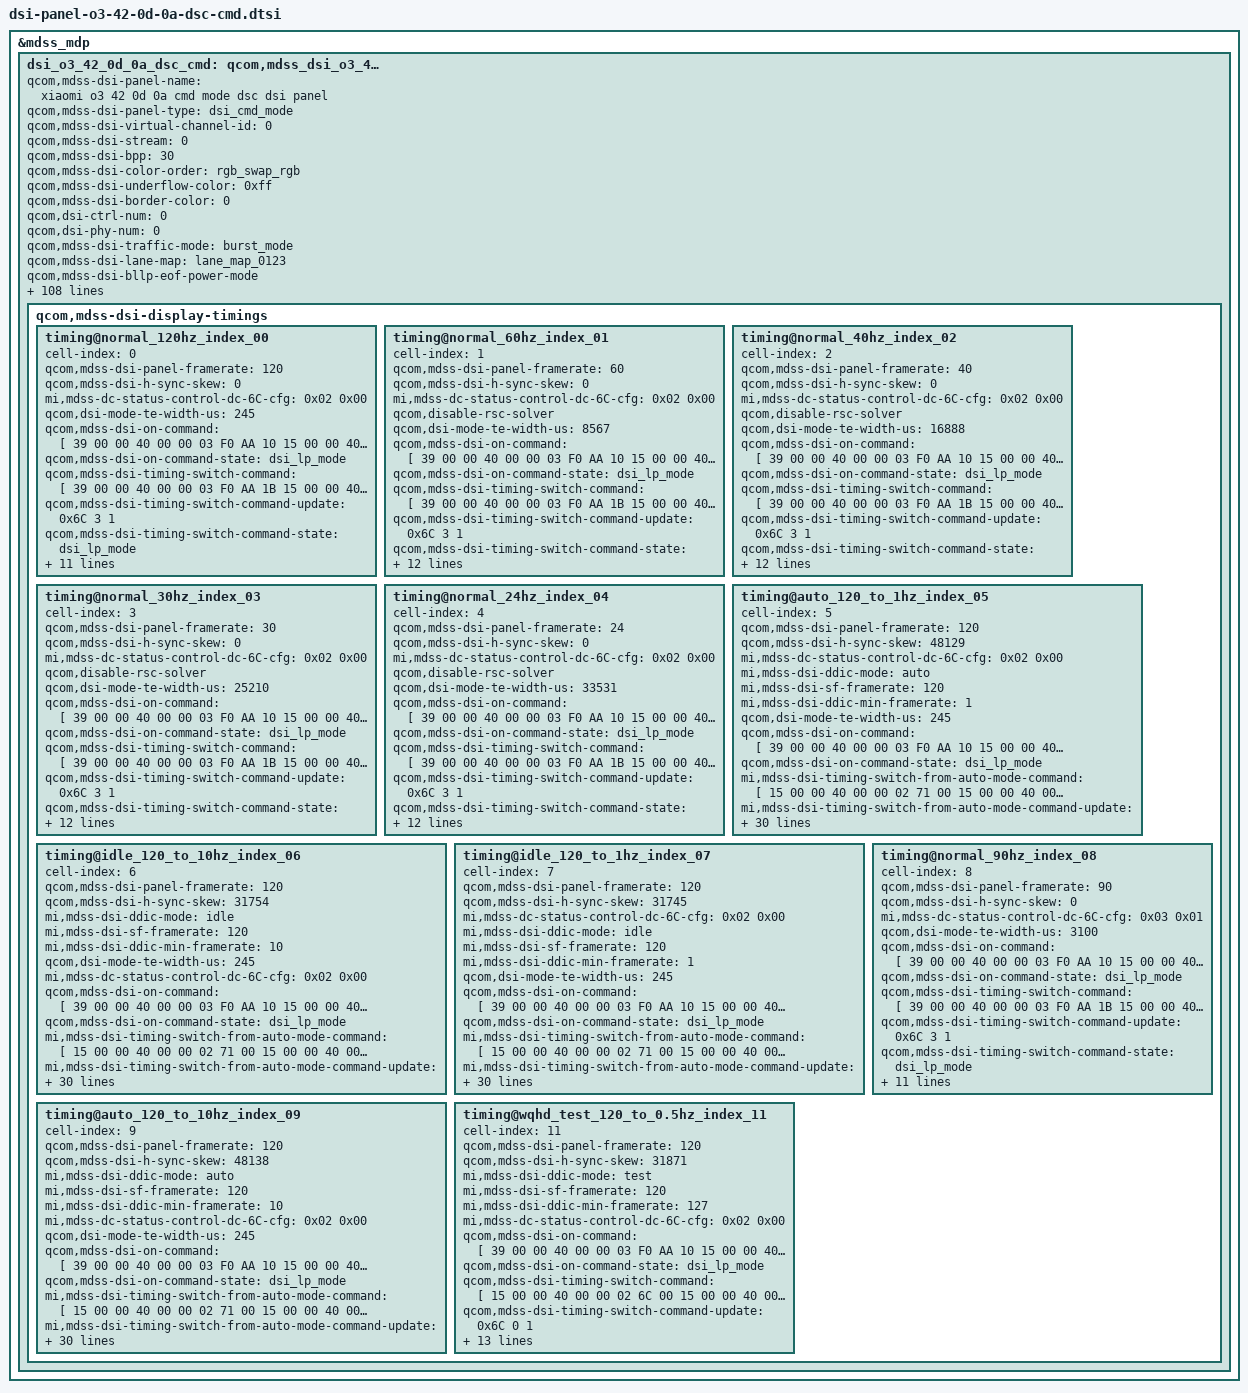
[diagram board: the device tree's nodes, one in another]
&mdss_mdp {
	dsi_o3_42_0d_0a_dsc_cmd: qcom,mdss_dsi_o3_42_0d_0a_dsc_cmd {
		qcom,mdss-dsi-panel-name = "xiaomi o3 42 0d 0a cmd mode dsc dsi panel";
		qcom,mdss-dsi-panel-type = "dsi_cmd_mode";
		qcom,mdss-dsi-virtual-channel-id = <0>;
		qcom,mdss-dsi-stream = <0>;
		qcom,mdss-dsi-bpp = <30>;
		qcom,mdss-dsi-color-order = "rgb_swap_rgb";
		qcom,mdss-dsi-underflow-color = <0xff>;
		qcom,mdss-dsi-border-color = <0>;
		qcom,dsi-ctrl-num = <0>;
		qcom,dsi-phy-num = <0>;

		qcom,mdss-dsi-traffic-mode = "burst_mode";
		qcom,mdss-dsi-lane-map = "lane_map_0123";
		qcom,mdss-dsi-bllp-eof-power-mode;
		qcom,mdss-dsi-bllp-power-mode;
		qcom,mdss-dsi-lane-0-state;
		qcom,mdss-dsi-lane-1-state;
		qcom,mdss-dsi-lane-2-state;
		qcom,mdss-dsi-lane-3-state;
		qcom,mdss-dsi-dma-trigger = "trigger_sw";
		qcom,mdss-dsi-mdp-trigger = "none";
		qcom,mdss-dsi-reset-sequence = <0 15>, <1 25>;
		qcom,mdss-pan-physical-width-dimension = <663>;
		qcom,mdss-pan-physical-height-dimension = <1473>;
		qcom,mdss-dsi-te-pin-select = <1>;
		qcom,mdss-dsi-wr-mem-start = <0x2c>;
		qcom,mdss-dsi-wr-mem-continue = <0x3c>;
		qcom,mdss-dsi-te-dcs-command = <1>;
		qcom,mdss-dsi-te-check-enable;
		qcom,mdss-dsi-te-using-te-pin;
		qcom,mdss-dsi-tx-eot-append;
		qcom,mdss-dsi-lp11-init;
		qcom,mdss-dsi-panel-hdr-enabled;
		qcom,mdss-dsi-panel-hdr-color-primaries = <14500 15500 32000 17000 15500 30000 8000 3000>;
		qcom,mdss-dsi-panel-peak-brightness = <32000000>;
		qcom,mdss-dsi-panel-blackness-level = <3230>;

		qcom,mdss-dsi-bl-inverted-dbv;
		qcom,bl-update-flag = "delay_until_first_frame";

		qcom,mdss-dsi-dma-schedule-line = <1>;
		qcom,mdss-dsi-dma-schedule-window = <50>;

		mi,panel-id = <0x00004F33 0x00420D0A>;

		mi,panel-on-dimming-delay = <120>;
		mi,max-brightness-clone = <16383>;

		mi,need-update-gamma-befor-init;

		/* IRQF_ONESHOT | IRQF_TRIGGER_HEIGH */
		mi,esd-err-irq-gpio = <&tlmm 87 0x2004>;
		mi,esd-err-irq-gpio-flag = <0x2004>;

		qcom,spr-pack-type = "pentile";
		/*
		 * ###############################################################
		 * # Pentile SPR phases for SM8750 and later
		 * ###############################################################
		 * # RG/BG Type A    BG/RG Type A    GR/GB Type A    GB/GR Type A
		 * # R B R B ...     B R B R ...      R B R B ...     B R B R ...
		 * #  G G G G ...     G G G G ...    G G G G ...     G G G G ...
		 * #
		 * # RG/BG Type B    BG/RG Type B    GR/GB Type B    GB/GR Type B
		 * #  G G G G ...     G G G G ...    G G G G ...     G G G G ...
		 * # R B R B ...     B R B R ...      R B R B ...     B R B R ...
		 * ###############################################################
		 */
		qcom,spr-pentile-pack-type = "RG-BG Type A";

		mi,mdss-dsi-panel-wp-read-command = [06 01 00 01 00 00 01 5C];
		mi,mdss-dsi-panel-wp-read-command-state = "dsi_hs_mode";
		mi,mdss-dsi-panel-wp-read-length = <8>;

		mi,mdss-dsi-panel-cell-id-read-command = [06 01 00 01 00 00 01 5A];
		mi,mdss-dsi-panel-cell-id-read-command-state = "dsi_hs_mode";
		mi,mdss-dsi-panel-cell-id-read-length = <13>;

		/* esd-check reg_read */
		qcom,esd-check-enabled;
		qcom,esd-aod-check-enabled;
		mi,mdss-dsi-panel-status-check-interval = <5000>;
		qcom,mdss-dsi-panel-status-check-mode = "reg_read";
		mi,mdss-dsi-panel-status-offset-command = [
			39 00 00 00 00 00 03 FF 5A 82
			39 00 00 00 00 00 02 65 01];
		qcom,mdss-dsi-panel-status-command = [
			06 01 00 00 00 00 01 F9
			06 01 00 00 00 00 01 70];
		mi,mdss-dsi-panel-status-after-command = [39 00 00 00 00 00 03 FF 5A 00];
		qcom,mdss-dsi-panel-status-command-state = "dsi_lp_mode";
		mi,mdss-dsi-panel-status-offset-command-state = "dsi_lp_mode";
		mi,mdss-dsi-panel-status-after-command-state = "dsi_lp_mode";
		qcom,mdss-dsi-panel-status-value = <0x08>, <0x12 0x00 0x00>;
		qcom,mdss-dsi-panel-status-read-length = <1>,<3>;

		mi,mdss-dsi-fac-bl-max-level = <2731>;
		mi,mdss-fac-brightness-max-level = <2731>;
		mi,flatmode-status-check-enabled;
		mi,mdss-dsi-panel-flatmode-status-offset-command = [
			39 00 00 00 00 00 03 F0 AA 11
		];
		mi,mdss-dsi-panel-flatmode-status-offset-command-state = "dsi_hs_mode";
		mi,mdss-dsi-panel-flatmode-status-command = [
			06 01 00 01 00 00 01 D5
		];
		mi,mdss-dsi-panel-flatmode-status-command-state = "dsi_hs_mode";
		mi,mdss-dsi-panel-flatmode-status-read-length = <1>;
		mi,mdss-dsi-panel-flatmode-on-status-value = <0x71>;

		mi,doze-hbm-dbv-level = <207>;
		mi,doze-lbm-dbv-level = <18>;

		mi,dc-feature-enabled;
		mi,ddic-round-corner-enabled;

		qcom,mdss-dsi-display-timings {
			timing@normal_120hz_index_00 {
				#include "dsi-panel-o3-42-0d-0a-dsc-cmd-common.dtsi"
				cell-index = <0>;
				qcom,mdss-dsi-panel-framerate = <120>;
				qcom,mdss-dsi-h-sync-skew = <0>;
				mi,mdss-dc-status-control-dc-6C-cfg = <0x02 0x00>;
				qcom,dsi-mode-te-width-us = <245>;

				qcom,mdss-dsi-on-command = [
					/*ELVSS DIM OFF*/
					39 00 00 40 00 00 03 F0 AA 10
					15 00 00 40 00 00 02 65 01
					15 00 00 40 00 00 02 D0 05
					15 00 00 40 00 00 02 03 01
					/*TE ON*/
					15 00 00 40 00 00 02 35 00
					/*brightness control*/
					15 00 00 40 00 00 02 53 28
					39 00 00 40 00 00 03 F0 AA 13
					15 00 00 40 00 00 02 C8 10
					15 00 00 40 00 00 02 D0 10
					15 00 00 40 00 00 02 E0 10
					15 00 00 40 00 00 02 E8 10
					39 00 00 40 00 00 03 51 00 00
					15 00 00 40 00 00 02 5E 00
					/*Demura on*/
					15 00 00 40 00 00 02 59 09
					//AGC
					39 00 00 40 00 00 03 FF 5A 81
					15 00 00 40 00 00 02 65 1B
					15 00 00 40 00 00 02 F8 04
					15 00 00 40 00 00 02 65 1A
					15 00 00 40 00 00 02 F8 0F
					15 00 00 40 00 00 02 65 0A
					15 00 00 00 00 00 02 F8 FB
					/* Auto Dimming OFF */
					39 00 00 40 00 00 03 F0 AA 1B
					/*Frame skip OFF (Auto Mode)*/
					15 00 00 40 00 00 02 D0 00
					/*Frame Skip Mode 1*/
					15 00 00 00 00 00 02 75 00
					/*120hz normal*/
					15 00 00 40 00 00 02 6C 00
					/*120hz*/
					15 00 00 40 00 00 02 71 00
					/*FIX TE OFF*/
					39 00 00 40 00 00 03 F0 AA 10
 					15 00 00 00 00 00 02 CF 16
					/*AOD1*/
					15 00 00 40 00 00 02 6D 00
					15 00 00 40 00 00 02 6F 02
					/*ANRF*/
					15 00 00 40 00 00 02 75 00
					/*PMIC1*/
					15 00 00 40 00 00 02 72 00
					/*PPS*/
					39 00 00 00 00 00 60 70 12 00 00 AB 21 00 0A 6E 04
							B0 00 1E 02 58 02 58 01 55 01
							D2 00 0A 01 88 00 32 00 0D 03
							97 11 48 08 00 0C 00 07 10 20
							00 06 0F 0F 33 0E 1C 2A 38 46
							54 62 69 70 77 79 7B 7D 7E 00
							82 11 40 19 C0 22 3E 32 7C 3A
							BA 3A F8 3B 38 3B 38 3B 76 4B
							76 4B 74 4B 74 5B B4 73 F4 01
							00 00 00 00 00 00
					/*Line1:RGBG Line2:BGRG*/
					39 00 00 40 00 00 03 F0 AA 10
					39 00 00 40 00 00 0E BD 10 02 31 46 75 8A B9 01 32 45 76 89 BA
					/*IC SPR OFF  AP SPR ON*/
					39 00 00 40 00 00 03 F0 AA 17
					15 00 00 40 00 00 02 B0 11
					39 00 00 40 00 00 07 C0 21 00 34 20 31 04
					15 00 00 40 00 00 02 65 06
					15 00 00 40 00 00 02 BF FF
					39 00 00 40 00 00 03 FF 5A 80
					15 00 00 40 00 00 02 65 0A
					39 00 00 40 00 00 03 F9 9E 8F
					15 00 00 40 00 00 02 65 0F
					15 00 00 40 00 00 02 F9 14
					/*optimize high load*/
					39 00 00 40 00 00 03 ff 5A 81
					15 00 00 40 00 00 02 65 03
					15 00 00 40 00 00 02 F3 24
					15 00 00 40 00 00 02 65 05
					15 00 00 40 00 00 02 F3 A0
					/*VREFP power on sequence*/
					39 00 00 40 00 00 03 FF 5A 81
					15 00 00 40 00 00 02 65 02
					39 00 00 40 00 00 05 FB D3 D3 D3 D3
					/*Active Low,ERR High*/
					39 00 00 40 00 00 03 F0 AA 10
					15 00 00 40 00 00 02 65 01
					15 00 00 00 00 00 02 CF 07
					//tp vsync
					39 00 00 40 00 00 03 F0 AA 10
					15 00 00 40 00 00 02 65 03
					15 00 00 00 00 00 02 CF 24
					/*AOD use PMIC Supply*/
					39 00 00 40 00 00 03 F0 AA 10
					15 00 00 40 00 00 02 B6 00
					//SRAM ECC by V Clear
					39 00 00 40 00 00 03 FF 5A 82
					15 00 00 40 00 00 02 65 04
					15 00 00 00 00 00 02 F8 10
					/*ACL*/
					39 00 00 40 00 00 03 F0 AA 11
					15 00 00 40 00 00 02 C0 00
					15 00 00 40 00 00 02 65 09
					39 00 00 40 00 00 04 C0 55 AA AA
					39 00 00 40 00 00 0C C1 03 34 03 99 03 34 03 FF FF A6 00
					15 00 00 40 00 00 02 55 01
					//open PMIC FD open DIC FD
					39 00 00 40 00 00 03 F0 AA 10
					15 00 00 40 00 00 02 65 07
					15 00 00 40 00 00 02 D0 00
					15 00 00 40 00 00 02 65 09
					39 00 00 40 00 00 03 D0 03 19
					15 00 00 40 00 00 02 65 0C
					15 00 00 40 00 00 02 D0 00
					15 00 00 40 00 00 02 65 0E
					39 00 00 40 00 00 03 D0 03 19
					15 00 00 40 00 00 02 65 11
					15 00 00 40 00 00 02 D0 19
					39 00 00 40 00 00 03 F0 AA 12
					15 00 00 40 00 00 02 65 0B
					15 00 00 40 00 00 02 D2 10
					39 00 00 40 00 00 03 F0 AA 10
					39 00 00 00 00 00 09 C4 34 34 34 34 34 34 34 34
					/* Display On */
					05 00 00 00 78 00 01 11
					05 00 00 00 00 00 01 29
				];
				qcom,mdss-dsi-on-command-state = "dsi_lp_mode";

				qcom,mdss-dsi-timing-switch-command = [
					/* Auto Dimming OFF */
					39 00 00 40 00 00 03 F0 AA 1B
					/*Frame skip OFF (Auto Mode)*/
					15 00 00 40 00 00 02 D0 00
					/*Frame Skip Mode 1*/
					15 00 00 00 00 00 02 75 00
					/* Frequency Select 120Hz */
					15 00 00 40 00 00 02 6C 00
					15 00 00 00 00 00 02 71 00
				];
				qcom,mdss-dsi-timing-switch-command-update = <0x6C 3 1>;
				qcom,mdss-dsi-timing-switch-command-state = "dsi_lp_mode";

				qcom,mdss-dsi-nolp-command = [
					05 00 00 40 00 00 01 38
					15 00 00 40 00 00 02 75 00
					39 00 00 40 00 00 03 F0 AA 1B
					15 00 00 40 00 00 02 D0 00
					39 00 00 40 00 00 03 51 00 00
					/*FIX TE OFF*/
					39 00 00 40 00 00 03 F0 AA 10
					15 00 00 00 09 00 02 CF 16
					/* Frequency Select 120Hz */
					15 00 00 40 00 00 02 6C 00
					15 00 00 00 00 00 02 71 00
				];
				qcom,mdss-dsi-nolp-command-update = <0x51 4 2>, <0x6C 7 1>;
				qcom,mdss-dsi-nolp-command-state = "dsi_lp_mode";

				mi,mdss-dsi-dc-on-command = [
					15 00 00 00 00 00 02 6C 02
				];
				mi,mdss-dsi-dc-on-command-state = "dsi_lp_mode";
				mi,mdss-dsi-dc-off-command = [
					15 00 00 00 00 00 02 6C 00
				];
				mi,mdss-dsi-dc-off-command-state = "dsi_lp_mode";
			};

			timing@normal_60hz_index_01 {
				#include "dsi-panel-o3-42-0d-0a-dsc-cmd-common.dtsi"
				cell-index = <1>;
				qcom,mdss-dsi-panel-framerate = <60>;
				qcom,mdss-dsi-h-sync-skew = <0>;
				mi,mdss-dc-status-control-dc-6C-cfg = <0x02 0x00>;
				qcom,disable-rsc-solver;
				qcom,dsi-mode-te-width-us = <8567>;

				qcom,mdss-dsi-on-command = [
					/*ELVSS DIM OFF*/
					39 00 00 40 00 00 03 F0 AA 10
					15 00 00 40 00 00 02 65 01
					15 00 00 40 00 00 02 D0 05
					15 00 00 40 00 00 02 03 01
					/*TE ON*/
					15 00 00 40 00 00 02 35 00
					/*brightness control*/
					15 00 00 40 00 00 02 53 28
					39 00 00 40 00 00 03 F0 AA 13
					15 00 00 40 00 00 02 C8 10
					15 00 00 40 00 00 02 D0 10
					15 00 00 40 00 00 02 E0 10
					15 00 00 40 00 00 02 E8 10
					39 00 00 40 00 00 03 51 00 00
					15 00 00 40 00 00 02 5E 00
					/*Demura on*/
					15 00 00 40 00 00 02 59 09
					//AGC
					39 00 00 40 00 00 03 FF 5A 81
					15 00 00 40 00 00 02 65 1B
					15 00 00 40 00 00 02 F8 04
					15 00 00 40 00 00 02 65 1A
					15 00 00 40 00 00 02 F8 0F
					15 00 00 40 00 00 02 65 0A
					15 00 00 00 00 00 02 F8 FB
					/* Auto Dimming OFF */
					39 00 00 40 00 00 03 F0 AA 1B
					/*Frame skip OFF (Auto Mode)*/
					15 00 00 40 00 00 02 D0 00
					/*Frame Skip Mode 1*/
					15 00 00 00 00 00 02 75 00
					/*120hz normal*/
					15 00 00 40 00 00 02 6C 00
					/*60hz*/
					39 00 00 40 00 00 04 71 01 01 00
					/*FIX TE OFF*/
					39 00 00 40 00 00 03 F0 AA 10
 					15 00 00 00 00 00 02 CF 16
					/*AOD1*/
					15 00 00 40 00 00 02 6D 00
					15 00 00 40 00 00 02 6F 02
					/*ANRF*/
					15 00 00 40 00 00 02 75 00
					/*PMIC1*/
					15 00 00 40 00 00 02 72 00
					/*PPS*/
					39 00 00 00 00 00 60 70 12 00 00 AB 21 00 0A 6E 04
							B0 00 1E 02 58 02 58 01 55 01
							D2 00 0A 01 88 00 32 00 0D 03
							97 11 48 08 00 0C 00 07 10 20
							00 06 0F 0F 33 0E 1C 2A 38 46
							54 62 69 70 77 79 7B 7D 7E 00
							82 11 40 19 C0 22 3E 32 7C 3A
							BA 3A F8 3B 38 3B 38 3B 76 4B
							76 4B 74 4B 74 5B B4 73 F4 01
							00 00 00 00 00 00
					/*Line1:RGBG Line2:BGRG*/
					39 00 00 40 00 00 03 F0 AA 10
					39 00 00 40 00 00 0E BD 10 02 31 46 75 8A B9 01 32 45 76 89 BA
					/*IC SPR OFF  AP SPR ON*/
					39 00 00 40 00 00 03 F0 AA 17
					15 00 00 40 00 00 02 B0 11
					39 00 00 40 00 00 07 C0 21 00 34 20 31 04
					15 00 00 40 00 00 02 65 06
					15 00 00 40 00 00 02 BF FF
					39 00 00 40 00 00 03 FF 5A 80
					15 00 00 40 00 00 02 65 0A
					39 00 00 40 00 00 03 F9 9E 8F
					15 00 00 40 00 00 02 65 0F
					15 00 00 40 00 00 02 F9 14
					/*optimize high load*/
					39 00 00 40 00 00 03 ff 5A 81
					15 00 00 40 00 00 02 65 03
					15 00 00 40 00 00 02 F3 24
					15 00 00 40 00 00 02 65 05
					15 00 00 40 00 00 02 F3 A0
					/*VREFP power on sequence*/
					39 00 00 40 00 00 03 FF 5A 81
					15 00 00 40 00 00 02 65 02
					39 00 00 40 00 00 05 FB D3 D3 D3 D3
					/*Active Low,ERR High*/
					39 00 00 40 00 00 03 F0 AA 10
					15 00 00 40 00 00 02 65 01
					15 00 00 00 00 00 02 CF 07
					//tp vsync
					39 00 00 40 00 00 03 F0 AA 10
					15 00 00 40 00 00 02 65 03
					15 00 00 00 00 00 02 CF 24
					/*AOD use PMIC Supply*/
					39 00 00 40 00 00 03 F0 AA 10
					15 00 00 40 00 00 02 B6 00
					//SRAM ECC by V Clear
					39 00 00 40 00 00 03 FF 5A 82
					15 00 00 40 00 00 02 65 04
					15 00 00 00 00 00 02 F8 10
					/*ACL*/
					39 00 00 40 00 00 03 F0 AA 11
					15 00 00 40 00 00 02 C0 00
					15 00 00 40 00 00 02 65 09
					39 00 00 40 00 00 04 C0 55 AA AA
					39 00 00 40 00 00 0C C1 03 34 03 99 03 34 03 FF FF A6 00
					15 00 00 40 00 00 02 55 01
					//open PMIC FD open DIC FD
					39 00 00 40 00 00 03 F0 AA 10
					15 00 00 40 00 00 02 65 07
					15 00 00 40 00 00 02 D0 00
					15 00 00 40 00 00 02 65 09
					39 00 00 40 00 00 03 D0 03 19
					15 00 00 40 00 00 02 65 0C
					15 00 00 40 00 00 02 D0 00
					15 00 00 40 00 00 02 65 0E
					39 00 00 40 00 00 03 D0 03 19
					15 00 00 40 00 00 02 65 11
					15 00 00 40 00 00 02 D0 19
					39 00 00 40 00 00 03 F0 AA 12
					15 00 00 40 00 00 02 65 0B
					15 00 00 40 00 00 02 D2 10
					39 00 00 40 00 00 03 F0 AA 10
					39 00 00 00 00 00 09 C4 34 34 34 34 34 34 34 34
					/* Display On */
					05 00 00 00 78 00 01 11
					05 00 00 00 00 00 01 29
				];
				qcom,mdss-dsi-on-command-state = "dsi_lp_mode";

				qcom,mdss-dsi-timing-switch-command = [
					/* Auto Dimming OFF */
					39 00 00 40 00 00 03 F0 AA 1B
					/*Frame skip OFF (Auto Mode)*/
					15 00 00 40 00 00 02 D0 00
					/*Frame Skip Mode 1*/
					15 00 00 00 00 00 02 75 00
					/* Frequency Select 120Hz */
					15 00 00 40 00 00 02 6C 00
					/* Frequency Select 60Hz */
					39 00 00 40 00 00 04 71 01 01 00
					/*FIX TE OFF*/
					39 00 00 40 00 00 03 F0 AA 10
					15 00 00 00 00 00 02 CF 16
				];
				qcom,mdss-dsi-timing-switch-command-update = <0x6C 3 1>;
				qcom,mdss-dsi-timing-switch-command-state = "dsi_lp_mode";

				qcom,mdss-dsi-nolp-command = [
					05 00 00 40 00 00 01 38
					15 00 00 40 00 00 02 75 00
					39 00 00 40 00 00 03 F0 AA 1B
					15 00 00 40 00 00 02 D0 00
					39 00 00 40 00 00 03 51 00 00
					/*FIX TE OFF*/
					39 00 00 40 00 00 03 F0 AA 10
					15 00 00 00 09 00 02 CF 16
					/* Frequency Select 120Hz */
					15 00 00 40 00 00 02 6C 00
					/* Frequency Select 60Hz */
					39 00 00 00 00 00 04 71 01 01 00
				];
				qcom,mdss-dsi-nolp-command-update = <0x51 4 2>, <0x6C 7 1>;
				qcom,mdss-dsi-nolp-command-state = "dsi_lp_mode";

				mi,mdss-dsi-dc-on-command = [
					15 00 00 00 00 00 02 6C 02
				];
				mi,mdss-dsi-dc-on-command-state = "dsi_lp_mode";
				mi,mdss-dsi-dc-off-command = [
					15 00 00 00 00 00 02 6C 00
				];
				mi,mdss-dsi-dc-off-command-state = "dsi_lp_mode";
			};

			timing@normal_40hz_index_02 {
				#include "dsi-panel-o3-42-0d-0a-dsc-cmd-common.dtsi"
				cell-index = <2>;
				qcom,mdss-dsi-panel-framerate = <40>;
				qcom,mdss-dsi-h-sync-skew = <0>;
				mi,mdss-dc-status-control-dc-6C-cfg = <0x02 0x00>;
				qcom,disable-rsc-solver;
				qcom,dsi-mode-te-width-us = <16888>;

				qcom,mdss-dsi-on-command = [
					/*ELVSS DIM OFF*/
					39 00 00 40 00 00 03 F0 AA 10
					15 00 00 40 00 00 02 65 01
					15 00 00 40 00 00 02 D0 05
					15 00 00 40 00 00 02 03 01
					/*TE ON*/
					15 00 00 40 00 00 02 35 00
					/*brightness control*/
					15 00 00 40 00 00 02 53 28
					39 00 00 40 00 00 03 F0 AA 13
					15 00 00 40 00 00 02 C8 10
					15 00 00 40 00 00 02 D0 10
					15 00 00 40 00 00 02 E0 10
					15 00 00 40 00 00 02 E8 10
					39 00 00 40 00 00 03 51 00 00
					15 00 00 40 00 00 02 5E 00
					/*Demura on*/
					15 00 00 40 00 00 02 59 09
					//AGC
					39 00 00 40 00 00 03 FF 5A 81
					15 00 00 40 00 00 02 65 1B
					15 00 00 40 00 00 02 F8 04
					15 00 00 40 00 00 02 65 1A
					15 00 00 40 00 00 02 F8 0F
					15 00 00 40 00 00 02 65 0A
					15 00 00 00 00 00 02 F8 FB
					/* Auto Dimming OFF */
					39 00 00 40 00 00 03 F0 AA 1B
					/*Frame skip OFF (Auto Mode)*/
					15 00 00 40 00 00 02 D0 00
					/*Frame Skip Mode 1*/
					15 00 00 00 00 00 02 75 00
					/*120hz normal*/
					15 00 00 40 00 00 02 6C 00
					/*40hz*/
					39 00 00 40 00 00 04 71 01 02 00
					/*FIX TE OFF*/
					39 00 00 40 00 00 03 F0 AA 10
 					15 00 00 00 00 00 02 CF 16
					/*AOD1*/
					15 00 00 40 00 00 02 6D 00
					15 00 00 40 00 00 02 6F 02
					/*ANRF*/
					15 00 00 40 00 00 02 75 00
					/*PMIC1*/
					15 00 00 40 00 00 02 72 00
					/*PPS*/
					39 00 00 00 00 00 60 70 12 00 00 AB 21 00 0A 6E 04
							B0 00 1E 02 58 02 58 01 55 01
							D2 00 0A 01 88 00 32 00 0D 03
							97 11 48 08 00 0C 00 07 10 20
							00 06 0F 0F 33 0E 1C 2A 38 46
							54 62 69 70 77 79 7B 7D 7E 00
							82 11 40 19 C0 22 3E 32 7C 3A
							BA 3A F8 3B 38 3B 38 3B 76 4B
							76 4B 74 4B 74 5B B4 73 F4 01
							00 00 00 00 00 00
					/*Line1:RGBG Line2:BGRG*/
					39 00 00 40 00 00 03 F0 AA 10
					39 00 00 40 00 00 0E BD 10 02 31 46 75 8A B9 01 32 45 76 89 BA
					/*IC SPR OFF  AP SPR ON*/
					39 00 00 40 00 00 03 F0 AA 17
					15 00 00 40 00 00 02 B0 11
					39 00 00 40 00 00 07 C0 21 00 34 20 31 04
					15 00 00 40 00 00 02 65 06
					15 00 00 40 00 00 02 BF FF
					39 00 00 40 00 00 03 FF 5A 80
					15 00 00 40 00 00 02 65 0A
					39 00 00 40 00 00 03 F9 9E 8F
					15 00 00 40 00 00 02 65 0F
					15 00 00 40 00 00 02 F9 14
					/*optimize high load*/
					39 00 00 40 00 00 03 ff 5A 81
					15 00 00 40 00 00 02 65 03
					15 00 00 40 00 00 02 F3 24
					15 00 00 40 00 00 02 65 05
					15 00 00 40 00 00 02 F3 A0
					/*VREFP power on sequence*/
					39 00 00 40 00 00 03 FF 5A 81
					15 00 00 40 00 00 02 65 02
					39 00 00 40 00 00 05 FB D3 D3 D3 D3
					/*Active Low,ERR High*/
					39 00 00 40 00 00 03 F0 AA 10
					15 00 00 40 00 00 02 65 01
					15 00 00 00 00 00 02 CF 07
					//tp vsync
					39 00 00 40 00 00 03 F0 AA 10
					15 00 00 40 00 00 02 65 03
					15 00 00 00 00 00 02 CF 24
					/*AOD use PMIC Supply*/
					39 00 00 40 00 00 03 F0 AA 10
					15 00 00 40 00 00 02 B6 00
					//SRAM ECC by V Clear
					39 00 00 40 00 00 03 FF 5A 82
					15 00 00 40 00 00 02 65 04
					15 00 00 00 00 00 02 F8 10
					/*ACL*/
					39 00 00 40 00 00 03 F0 AA 11
					15 00 00 40 00 00 02 C0 00
					15 00 00 40 00 00 02 65 09
					39 00 00 40 00 00 04 C0 55 AA AA
					39 00 00 40 00 00 0C C1 03 34 03 99 03 34 03 FF FF A6 00
					15 00 00 40 00 00 02 55 01
					//open PMIC FD open DIC FD
					39 00 00 40 00 00 03 F0 AA 10
					15 00 00 40 00 00 02 65 07
					15 00 00 40 00 00 02 D0 00
					15 00 00 40 00 00 02 65 09
					39 00 00 40 00 00 03 D0 03 19
					15 00 00 40 00 00 02 65 0C
					15 00 00 40 00 00 02 D0 00
					15 00 00 40 00 00 02 65 0E
					39 00 00 40 00 00 03 D0 03 19
					15 00 00 40 00 00 02 65 11
					15 00 00 40 00 00 02 D0 19
					39 00 00 40 00 00 03 F0 AA 12
					15 00 00 40 00 00 02 65 0B
					15 00 00 40 00 00 02 D2 10
					39 00 00 40 00 00 03 F0 AA 10
					39 00 00 00 00 00 09 C4 34 34 34 34 34 34 34 34
					/* Display On */
					05 00 00 00 78 00 01 11
					05 00 00 00 00 00 01 29
				];
				qcom,mdss-dsi-on-command-state = "dsi_lp_mode";

				qcom,mdss-dsi-timing-switch-command = [
					/* Auto Dimming OFF */
					39 00 00 40 00 00 03 F0 AA 1B
					/*Frame skip OFF (Auto Mode)*/
					15 00 00 40 00 00 02 D0 00
					/*Frame Skip Mode 1*/
					15 00 00 40 00 00 02 75 00
					/* Frequency Select 120Hz */
					15 00 00 40 00 00 02 6C 00
					/*40HZ*/
					39 00 00 40 00 00 04 71 01 02 00
					/*FIX TE OFF*/
					39 00 00 40 00 00 03 F0 AA 10
					15 00 00 00 00 00 02 CF 16
				];
				qcom,mdss-dsi-timing-switch-command-update = <0x6C 3 1>;
				qcom,mdss-dsi-timing-switch-command-state = "dsi_lp_mode";

				qcom,mdss-dsi-nolp-command = [
					05 00 00 40 00 00 01 38
					15 00 00 40 00 00 02 75 00
					39 00 00 40 00 00 03 F0 AA 1B
					15 00 00 40 00 00 02 D0 00
					39 00 00 40 00 00 03 51 00 00
					/*FIX TE OFF*/
					39 00 00 40 00 00 03 F0 AA 10
					15 00 00 00 09 00 02 CF 16
					/* Frequency Select 120Hz */
					15 00 00 40 00 00 02 6C 00
					/*40HZ*/
					39 00 00 00 00 00 04 71 01 02 00
				];
				qcom,mdss-dsi-nolp-command-update = <0x51 4 2>, <0x6C 7 1>;
				qcom,mdss-dsi-nolp-command-state = "dsi_lp_mode";

				mi,mdss-dsi-dc-on-command = [
					15 00 00 00 00 00 02 6C 02
				];
				mi,mdss-dsi-dc-on-command-state = "dsi_lp_mode";
				mi,mdss-dsi-dc-off-command = [
					15 00 00 00 00 00 02 6C 00
				];
				mi,mdss-dsi-dc-off-command-state = "dsi_lp_mode";
			};

			timing@normal_30hz_index_03 {
				#include "dsi-panel-o3-42-0d-0a-dsc-cmd-common.dtsi"
				cell-index = <3>;
				qcom,mdss-dsi-panel-framerate = <30>;
				qcom,mdss-dsi-h-sync-skew = <0>;
				mi,mdss-dc-status-control-dc-6C-cfg = <0x02 0x00>;
				qcom,disable-rsc-solver;
				qcom,dsi-mode-te-width-us = <25210>;

				qcom,mdss-dsi-on-command = [
					/*ELVSS DIM ON*/
					39 00 00 40 00 00 03 F0 AA 10
					15 00 00 40 00 00 02 65 01
					15 00 00 40 00 00 02 D0 05
					15 00 00 40 00 00 02 03 01
					/*TE ON*/
					15 00 00 40 00 00 02 35 00
					/*brightness control*/
					15 00 00 40 00 00 02 53 28
					39 00 00 40 00 00 03 F0 AA 13
					15 00 00 40 00 00 02 C8 10
					15 00 00 40 00 00 02 D0 10
					15 00 00 40 00 00 02 E0 10
					15 00 00 40 00 00 02 E8 10
					39 00 00 40 00 00 03 51 00 00
					15 00 00 40 00 00 02 5E 00
					/*Demura on*/
					15 00 00 40 00 00 02 59 09
					//AGC
					39 00 00 40 00 00 03 FF 5A 81
					15 00 00 40 00 00 02 65 1B
					15 00 00 40 00 00 02 F8 04
					15 00 00 40 00 00 02 65 1A
					15 00 00 40 00 00 02 F8 0F
					15 00 00 40 00 00 02 65 0A
					15 00 00 00 00 00 02 F8 FB
					/* Auto Dimming OFF */
					39 00 00 40 00 00 03 F0 AA 1B
					/*Frame skip OFF (Auto Mode)*/
					15 00 00 40 00 00 02 D0 00
					/*Frame Skip Mode 1*/
					15 00 00 00 00 00 02 75 00
					/*120hz normal*/
					15 00 00 40 00 00 02 6C 00
					/*30hz*/
					39 00 00 40 00 00 04 71 01 03 00
					/*FIX TE OFF*/
					39 00 00 40 00 00 03 F0 AA 10
 					15 00 00 00 00 00 02 CF 16
					/*AOD1*/
					15 00 00 40 00 00 02 6D 00
					15 00 00 40 00 00 02 6F 02
					/*ANRF*/
					15 00 00 40 00 00 02 75 00
					/*PMIC1*/
					15 00 00 40 00 00 02 72 00
					/*PPS*/
					39 00 00 00 00 00 60 70 12 00 00 AB 21 00 0A 6E 04
							B0 00 1E 02 58 02 58 01 55 01
							D2 00 0A 01 88 00 32 00 0D 03
							97 11 48 08 00 0C 00 07 10 20
							00 06 0F 0F 33 0E 1C 2A 38 46
							54 62 69 70 77 79 7B 7D 7E 00
							82 11 40 19 C0 22 3E 32 7C 3A
							BA 3A F8 3B 38 3B 38 3B 76 4B
							76 4B 74 4B 74 5B B4 73 F4 01
							00 00 00 00 00 00
					/*Line1:RGBG Line2:BGRG*/
					39 00 00 40 00 00 03 F0 AA 10
					39 00 00 40 00 00 0E BD 10 02 31 46 75 8A B9 01 32 45 76 89 BA
					/*IC SPR OFF  AP SPR ON*/
					39 00 00 40 00 00 03 F0 AA 17
					15 00 00 40 00 00 02 B0 11
					39 00 00 40 00 00 07 C0 21 00 34 20 31 04
					15 00 00 40 00 00 02 65 06
					15 00 00 40 00 00 02 BF FF
					39 00 00 40 00 00 03 FF 5A 80
					15 00 00 40 00 00 02 65 0A
					39 00 00 40 00 00 03 F9 9E 8F
					15 00 00 40 00 00 02 65 0F
					15 00 00 40 00 00 02 F9 14
					/*optimize high load*/
					39 00 00 40 00 00 03 ff 5A 81
					15 00 00 40 00 00 02 65 03
					15 00 00 40 00 00 02 F3 24
					15 00 00 40 00 00 02 65 05
					15 00 00 40 00 00 02 F3 A0
					/*VREFP power on sequence*/
					39 00 00 40 00 00 03 FF 5A 81
					15 00 00 40 00 00 02 65 02
					39 00 00 40 00 00 05 FB D3 D3 D3 D3
					/*Active Low,ERR High*/
					39 00 00 40 00 00 03 F0 AA 10
					15 00 00 40 00 00 02 65 01
					15 00 00 00 00 00 02 CF 07
					//tp vsync
					39 00 00 40 00 00 03 F0 AA 10
					15 00 00 40 00 00 02 65 03
					15 00 00 00 00 00 02 CF 24
					/*AOD use PMIC Supply*/
					39 00 00 40 00 00 03 F0 AA 10
					15 00 00 40 00 00 02 B6 00
					//SRAM ECC by V Clear
					39 00 00 40 00 00 03 FF 5A 82
					15 00 00 40 00 00 02 65 04
					15 00 00 00 00 00 02 F8 10
					/*ACL*/
					39 00 00 40 00 00 03 F0 AA 11
					15 00 00 40 00 00 02 C0 00
					15 00 00 40 00 00 02 65 09
					39 00 00 40 00 00 04 C0 55 AA AA
					39 00 00 40 00 00 0C C1 03 34 03 99 03 34 03 FF FF A6 00
					15 00 00 40 00 00 02 55 01
					//open PMIC FD open DIC FD
					39 00 00 40 00 00 03 F0 AA 10
					15 00 00 40 00 00 02 65 07
					15 00 00 40 00 00 02 D0 00
					15 00 00 40 00 00 02 65 09
					39 00 00 40 00 00 03 D0 03 19
					15 00 00 40 00 00 02 65 0C
					15 00 00 40 00 00 02 D0 00
					15 00 00 40 00 00 02 65 0E
					39 00 00 40 00 00 03 D0 03 19
					15 00 00 40 00 00 02 65 11
					15 00 00 40 00 00 02 D0 19
					39 00 00 40 00 00 03 F0 AA 12
					15 00 00 40 00 00 02 65 0B
					15 00 00 40 00 00 02 D2 10
					39 00 00 40 00 00 03 F0 AA 10
					39 00 00 00 00 00 09 C4 34 34 34 34 34 34 34 34
					/* Display On */
					05 00 00 00 78 00 01 11
					05 00 00 00 00 00 01 29
				];
				qcom,mdss-dsi-on-command-state = "dsi_lp_mode";

				qcom,mdss-dsi-timing-switch-command = [
					/* Auto Dimming OFF */
					39 00 00 40 00 00 03 F0 AA 1B
					/*Frame skip OFF (Auto Mode)*/
					15 00 00 40 00 00 02 D0 00
					/*Frame Skip Mode 1*/
					15 00 00 40 00 00 02 75 00
					/* Frequency Select 120Hz */
					15 00 00 40 00 00 02 6C 00
					/*30HZ*/
					39 00 00 40 00 00 04 71 01 03 00
					/*FIX TE OFF*/
					39 00 00 40 00 00 03 F0 AA 10
					15 00 00 00 00 00 02 CF 16
				];
				qcom,mdss-dsi-timing-switch-command-update = <0x6C 3 1>;
				qcom,mdss-dsi-timing-switch-command-state = "dsi_lp_mode";

				qcom,mdss-dsi-nolp-command = [
					05 00 00 40 00 00 01 38
					15 00 00 40 00 00 02 75 00
					39 00 00 40 00 00 03 F0 AA 1B
					15 00 00 40 00 00 02 D0 00
					39 00 00 40 00 00 03 51 00 00
					/*FIX TE OFF*/
					39 00 00 40 00 00 03 F0 AA 10
					15 00 00 00 09 00 02 CF 16
					/* Frequency Select 120Hz */
					15 00 00 40 00 00 02 6C 00
					/*30HZ*/
					39 00 00 00 00 00 04 71 01 03 00
				];
				qcom,mdss-dsi-nolp-command-update = <0x51 4 2>, <0x6C 7 1>;
				qcom,mdss-dsi-nolp-command-state = "dsi_lp_mode";

				mi,mdss-dsi-dc-on-command = [
					15 00 00 00 00 00 02 6C 02
				];
				mi,mdss-dsi-dc-on-command-state = "dsi_lp_mode";
				mi,mdss-dsi-dc-off-command = [
					15 00 00 00 00 00 02 6C 00
				];
				mi,mdss-dsi-dc-off-command-state = "dsi_lp_mode";
			};

			timing@normal_24hz_index_04 {
				#include "dsi-panel-o3-42-0d-0a-dsc-cmd-common.dtsi"
				cell-index = <4>;
				qcom,mdss-dsi-panel-framerate = <24>;
				qcom,mdss-dsi-h-sync-skew = <0>;
				mi,mdss-dc-status-control-dc-6C-cfg = <0x02 0x00>;
				qcom,disable-rsc-solver;
				qcom,dsi-mode-te-width-us = <33531>;

				qcom,mdss-dsi-on-command = [
					/*ELVSS DIM OFF*/
					39 00 00 40 00 00 03 F0 AA 10
					15 00 00 40 00 00 02 65 01
					15 00 00 40 00 00 02 D0 05
					15 00 00 40 00 00 02 03 01
					/*TE ON*/
					15 00 00 40 00 00 02 35 00
					/*brightness control*/
					15 00 00 40 00 00 02 53 28
					39 00 00 40 00 00 03 F0 AA 13
					15 00 00 40 00 00 02 C8 10
					15 00 00 40 00 00 02 D0 10
					15 00 00 40 00 00 02 E0 10
					15 00 00 40 00 00 02 E8 10
					39 00 00 40 00 00 03 51 00 00
					15 00 00 40 00 00 02 5E 00
					/*Demura on*/
					15 00 00 40 00 00 02 59 09
					//AGC
					39 00 00 40 00 00 03 FF 5A 81
					15 00 00 40 00 00 02 65 1B
					15 00 00 40 00 00 02 F8 04
					15 00 00 40 00 00 02 65 1A
					15 00 00 40 00 00 02 F8 0F
					15 00 00 40 00 00 02 65 0A
					15 00 00 00 00 00 02 F8 FB
					/* Auto Dimming OFF */
					39 00 00 40 00 00 03 F0 AA 1B
					/*Frame skip OFF (Auto Mode)*/
					15 00 00 40 00 00 02 D0 00
					/*Frame Skip Mode 1*/
					15 00 00 00 00 00 02 75 00
					/*120hz normal*/
					15 00 00 40 00 00 02 6C 00
					/*24hz*/
					39 00 00 40 00 00 04 71 01 04 00
					/*FIX TE OFF*/
					39 00 00 40 00 00 03 F0 AA 10
 					15 00 00 00 00 00 02 CF 16
					/*AOD1*/
					15 00 00 40 00 00 02 6D 00
					15 00 00 40 00 00 02 6F 02
					/*ANRF*/
					15 00 00 40 00 00 02 75 00
					/*PMIC1*/
					15 00 00 40 00 00 02 72 00
					/*PPS*/
					39 00 00 00 00 00 60 70 12 00 00 AB 21 00 0A 6E 04
							B0 00 1E 02 58 02 58 01 55 01
							D2 00 0A 01 88 00 32 00 0D 03
							97 11 48 08 00 0C 00 07 10 20
							00 06 0F 0F 33 0E 1C 2A 38 46
							54 62 69 70 77 79 7B 7D 7E 00
							82 11 40 19 C0 22 3E 32 7C 3A
							BA 3A F8 3B 38 3B 38 3B 76 4B
							76 4B 74 4B 74 5B B4 73 F4 01
							00 00 00 00 00 00
					/*Line1:RGBG Line2:BGRG*/
					39 00 00 40 00 00 03 F0 AA 10
					39 00 00 40 00 00 0E BD 10 02 31 46 75 8A B9 01 32 45 76 89 BA
					/*IC SPR OFF  AP SPR ON*/
					39 00 00 40 00 00 03 F0 AA 17
					15 00 00 40 00 00 02 B0 11
					39 00 00 40 00 00 07 C0 21 00 34 20 31 04
					15 00 00 40 00 00 02 65 06
					15 00 00 40 00 00 02 BF FF
					39 00 00 40 00 00 03 FF 5A 80
					15 00 00 40 00 00 02 65 0A
					39 00 00 40 00 00 03 F9 9E 8F
					15 00 00 40 00 00 02 65 0F
					15 00 00 40 00 00 02 F9 14
					/*optimize high load*/
					39 00 00 40 00 00 03 ff 5A 81
					15 00 00 40 00 00 02 65 03
					15 00 00 40 00 00 02 F3 24
					15 00 00 40 00 00 02 65 05
					15 00 00 40 00 00 02 F3 A0
					/*VREFP power on sequence*/
					39 00 00 40 00 00 03 FF 5A 81
					15 00 00 40 00 00 02 65 02
					39 00 00 40 00 00 05 FB D3 D3 D3 D3
					/*Active Low,ERR High*/
					39 00 00 40 00 00 03 F0 AA 10
					15 00 00 40 00 00 02 65 01
					15 00 00 00 00 00 02 CF 07
					//tp vsync
					39 00 00 40 00 00 03 F0 AA 10
					15 00 00 40 00 00 02 65 03
					15 00 00 00 00 00 02 CF 24
					/*AOD use PMIC Supply*/
					39 00 00 40 00 00 03 F0 AA 10
					15 00 00 40 00 00 02 B6 00
					//SRAM ECC by V Clear
					39 00 00 40 00 00 03 FF 5A 82
					15 00 00 40 00 00 02 65 04
					15 00 00 00 00 00 02 F8 10
					/*ACL*/
					39 00 00 40 00 00 03 F0 AA 11
					15 00 00 40 00 00 02 C0 00
					15 00 00 40 00 00 02 65 09
					39 00 00 40 00 00 04 C0 55 AA AA
					39 00 00 40 00 00 0C C1 03 34 03 99 03 34 03 FF FF A6 00
					15 00 00 40 00 00 02 55 01
					//open PMIC FD open DIC FD
					39 00 00 40 00 00 03 F0 AA 10
					15 00 00 40 00 00 02 65 07
					15 00 00 40 00 00 02 D0 00
					15 00 00 40 00 00 02 65 09
					39 00 00 40 00 00 03 D0 03 19
					15 00 00 40 00 00 02 65 0C
					15 00 00 40 00 00 02 D0 00
					15 00 00 40 00 00 02 65 0E
					39 00 00 40 00 00 03 D0 03 19
					15 00 00 40 00 00 02 65 11
					15 00 00 40 00 00 02 D0 19
					39 00 00 40 00 00 03 F0 AA 12
					15 00 00 40 00 00 02 65 0B
					15 00 00 40 00 00 02 D2 10
					39 00 00 40 00 00 03 F0 AA 10
					39 00 00 00 00 00 09 C4 34 34 34 34 34 34 34 34
					/* Display On */
					05 00 00 00 78 00 01 11
					05 00 00 00 00 00 01 29
				];
				qcom,mdss-dsi-on-command-state = "dsi_lp_mode";

				qcom,mdss-dsi-timing-switch-command = [
					/* Auto Dimming OFF */
					39 00 00 40 00 00 03 F0 AA 1B
					/*Frame skip OFF (Auto Mode)*/
					15 00 00 40 00 00 02 D0 00
					/*Frame Skip Mode 1*/
					15 00 00 40 00 00 02 75 00
					/* Frequency Select 120Hz */
					15 00 00 40 00 00 02 6C 00
					/*24HZ*/
					39 00 00 40 00 00 04 71 01 04 00
					/*FIX TE OFF*/
					39 00 00 40 00 00 03 F0 AA 10
					15 00 00 00 00 00 02 CF 16
				];
				qcom,mdss-dsi-timing-switch-command-update = <0x6C 3 1>;
				qcom,mdss-dsi-timing-switch-command-state = "dsi_lp_mode";

				qcom,mdss-dsi-nolp-command = [
					05 00 00 40 00 00 01 38
					15 00 00 40 00 00 02 75 00
					39 00 00 40 00 00 03 F0 AA 1B
					15 00 00 40 00 00 02 D0 00
					39 00 00 40 00 00 03 51 00 00
					/*FIX TE OFF*/
					39 00 00 40 00 00 03 F0 AA 10
					15 00 00 00 09 00 02 CF 16
					/* Frequency Select 120Hz */
					15 00 00 40 00 00 02 6C 00
					/*24HZ*/
					39 00 00 00 00 00 04 71 01 04 00
				];
				qcom,mdss-dsi-nolp-command-update = <0x51 4 2>, <0x6C 7 1>;
				qcom,mdss-dsi-nolp-command-state = "dsi_lp_mode";

				mi,mdss-dsi-dc-on-command = [
					15 00 00 00 00 00 02 6C 02
				];
				mi,mdss-dsi-dc-on-command-state = "dsi_lp_mode";
				mi,mdss-dsi-dc-off-command = [
					15 00 00 00 00 00 02 6C 00
				];
				mi,mdss-dsi-dc-off-command-state = "dsi_lp_mode";
			};

			timing@auto_120_to_1hz_index_05 {
				#include "dsi-panel-o3-42-0d-0a-dsc-cmd-common.dtsi"
				cell-index = <5>;
				qcom,mdss-dsi-panel-framerate = <120>;
				/* ---------------------------- */
				/* | 15 - 14 | 13 - 7 | 6 - 0 | */
				/* ---------------------------- */
				/* |   mode  | sf fps | min fps| */
				/* ---------------------------- -*/
				/* mode: 1 idle, 2 auto, 3 qsync */
				/*   2 << 14 | 120 << 7 | 1     */
				qcom,mdss-dsi-h-sync-skew = <48129>;
				mi,mdss-dc-status-control-dc-6C-cfg = <0x02 0x00>;
				mi,mdss-dsi-ddic-mode = "auto";
				mi,mdss-dsi-sf-framerate = <120>;
				mi,mdss-dsi-ddic-min-framerate = <1>;
				qcom,dsi-mode-te-width-us = <245>;

				qcom,mdss-dsi-on-command = [
					/*ELVSS DIM OFF*/
					39 00 00 40 00 00 03 F0 AA 10
					15 00 00 40 00 00 02 65 01
					15 00 00 40 00 00 02 D0 05
					15 00 00 40 00 00 02 03 01
					/*TE ON*/
					15 00 00 40 00 00 02 35 00
					/*brightness control*/
					15 00 00 40 00 00 02 53 28
					39 00 00 40 00 00 03 F0 AA 13
					15 00 00 40 00 00 02 C8 10
					15 00 00 40 00 00 02 D0 10
					15 00 00 40 00 00 02 E0 10
					15 00 00 40 00 00 02 E8 10
					39 00 00 40 00 00 03 51 00 00
					15 00 00 40 00 00 02 5E 00
					/*Demura on*/
					15 00 00 40 00 00 02 59 09
					//AGC
					39 00 00 40 00 00 03 FF 5A 81
					15 00 00 40 00 00 02 65 1B
					15 00 00 40 00 00 02 F8 04
					15 00 00 40 00 00 02 65 1A
					15 00 00 40 00 00 02 F8 0F
					15 00 00 40 00 00 02 65 0A
					15 00 00 00 00 00 02 F8 FB
					/* Frequency Select 120Hz */
					15 00 00 40 00 00 02 6C 00
					15 00 00 40 00 00 02 71 00
					15 00 00 40 00 00 02 75 01
					39 00 00 40 00 00 03 F0 AA 1B
					15 00 00 40 00 00 02 65 0C
					39 00 00 40 00 00 05 D5 77 77 77 77
					15 00 00 40 00 00 02 65 0C
					39 00 00 40 00 00 05 D7 77 77 77 77
					39 00 00 40 00 00 0E D2 04 01 03 04 0B 0B 0B 0B 0B 00 0E E0 00
					15 00 00 40 00 00 02 D0 11
					/*page 11*/
					39 00 00 40 00 00 03 F0 AA 1B
					/*Frame skip OFF*/
					15 00 00 40 00 00 02 D0 00
					/*FIX TE ON*/
					39 00 00 40 00 00 03 F0 AA 10
 					15 00 00 00 00 00 02 CF 09
					/*AOD1*/
					15 00 00 40 00 00 02 6D 00
					15 00 00 40 00 00 02 6F 02
					/*ANRF*/
					15 00 00 40 00 00 02 75 00
					/*PMIC1*/
					15 00 00 40 00 00 02 72 00
					/*PPS*/
					39 00 00 00 00 00 60 70 12 00 00 AB 21 00 0A 6E 04
							B0 00 1E 02 58 02 58 01 55 01
							D2 00 0A 01 88 00 32 00 0D 03
							97 11 48 08 00 0C 00 07 10 20
							00 06 0F 0F 33 0E 1C 2A 38 46
							54 62 69 70 77 79 7B 7D 7E 00
							82 11 40 19 C0 22 3E 32 7C 3A
							BA 3A F8 3B 38 3B 38 3B 76 4B
							76 4B 74 4B 74 5B B4 73 F4 01
							00 00 00 00 00 00
					/*Line1:RGBG Line2:BGRG*/
					39 00 00 40 00 00 03 F0 AA 10
					39 00 00 40 00 00 0E BD 10 02 31 46 75 8A B9 01 32 45 76 89 BA
					/*IC SPR OFF  AP SPR ON*/
					39 00 00 40 00 00 03 F0 AA 17
					15 00 00 40 00 00 02 B0 11
					39 00 00 40 00 00 07 C0 21 00 34 20 31 04
					15 00 00 40 00 00 02 65 06
					15 00 00 40 00 00 02 BF FF
					39 00 00 40 00 00 03 FF 5A 80
					15 00 00 40 00 00 02 65 0A
					39 00 00 40 00 00 03 F9 9E 8F
					15 00 00 40 00 00 02 65 0F
					15 00 00 40 00 00 02 F9 14
					/*optimize high load*/
					39 00 00 40 00 00 03 ff 5A 81
					15 00 00 40 00 00 02 65 03
					15 00 00 40 00 00 02 F3 24
					15 00 00 40 00 00 02 65 05
					15 00 00 40 00 00 02 F3 A0
					/*VREFP power on sequence*/
					39 00 00 40 00 00 03 FF 5A 81
					15 00 00 40 00 00 02 65 02
					39 00 00 40 00 00 05 FB D3 D3 D3 D3
					/*Active Low,ERR High*/
					39 00 00 40 00 00 03 F0 AA 10
					15 00 00 40 00 00 02 65 01
					15 00 00 00 00 00 02 CF 07
					//tp vsync
					39 00 00 40 00 00 03 F0 AA 10
					15 00 00 40 00 00 02 65 03
					15 00 00 00 00 00 02 CF 24
					/*AOD use PMIC Supply*/
					39 00 00 40 00 00 03 F0 AA 10
					15 00 00 40 00 00 02 B6 00
					//SRAM ECC by V Clear
					39 00 00 40 00 00 03 FF 5A 82
					15 00 00 40 00 00 02 65 04
					15 00 00 00 00 00 02 F8 10
					/*ACL*/
					39 00 00 40 00 00 03 F0 AA 11
					15 00 00 40 00 00 02 C0 00
					15 00 00 40 00 00 02 65 09
					39 00 00 40 00 00 04 C0 55 AA AA
					39 00 00 40 00 00 0C C1 03 34 03 99 03 34 03 FF FF A6 00
					15 00 00 40 00 00 02 55 01
					//open PMIC FD open DIC FD
					39 00 00 40 00 00 03 F0 AA 10
					15 00 00 40 00 00 02 65 07
					15 00 00 40 00 00 02 D0 00
					15 00 00 40 00 00 02 65 09
					39 00 00 40 00 00 03 D0 03 19
					15 00 00 40 00 00 02 65 0C
					15 00 00 40 00 00 02 D0 00
					15 00 00 40 00 00 02 65 0E
					39 00 00 40 00 00 03 D0 03 19
					15 00 00 40 00 00 02 65 11
					15 00 00 40 00 00 02 D0 19
					39 00 00 40 00 00 03 F0 AA 12
					15 00 00 40 00 00 02 65 0B
					15 00 00 40 00 00 02 D2 10
					39 00 00 40 00 00 03 F0 AA 10
					39 00 00 00 00 00 09 C4 34 34 34 34 34 34 34 34
					/* Display On */
					05 00 00 00 78 00 01 11
					05 00 00 00 00 00 01 29
				];
				qcom,mdss-dsi-on-command-state = "dsi_lp_mode";

				mi,mdss-dsi-timing-switch-from-auto-mode-command = [
					//AUTO 120HZ 10HZ 1HZ 30HZ
					/*Frame skip OFF (Auto Mode)*/
					15 00 00 40 00 00 02 71 00
					/* Frequency Select 120Hz */
					15 00 00 40 00 00 02 6C 00
					/* Auto Dimming OFF */
					39 00 00 40 00 00 03 F0 AA 1B
					/*Frame skip OFF (Auto Mode)*/
					15 00 00 40 00 00 02 D0 00
					/*Frame Skip Mode 1*/
					15 00 00 00 0A 00 02 75 00
				];
				mi,mdss-dsi-timing-switch-from-auto-mode-command-update = <0x6C 1 1>;
				mi,mdss-dsi-timing-switch-from-auto-mode-command-state = "dsi_lp_mode";

				mi,mdss-dsi-timing-switch-from-skip-mode-command = [
					//FORM 60HZ 40HZ
					/*Frame skip OFF (Auto Mode)*/
					15 00 00 40 00 00 02 71 00
					/* Frequency Select 120Hz */
					15 00 00 00 0A 00 02 6C 00
				];
				mi,mdss-dsi-timing-switch-from-skip-mode-command-update = <0x6C 1 1>;
				mi,mdss-dsi-timing-switch-from-skip-mode-command-state = "dsi_lp_mode";

				mi,mdss-dsi-timing-switch-from-normal-mode-command = [
					//from 120hz 90hz
					/* Frequency Select 120Hz */
					15 00 00 00 00 00 02 6C 00
				];
				mi,mdss-dsi-timing-switch-from-normal-mode-command-update = <0x6C 0 1>;
				mi,mdss-dsi-timing-switch-from-normal-mode-command-state = "dsi_lp_mode";

				qcom,mdss-dsi-timing-switch-command = [
					/* 120→60→30→24→10*30→1 */
					15 00 00 40 00 00 02 71 00
					15 00 00 40 00 00 02 75 01
					39 00 00 40 00 00 03 F0 AA 1B
					15 00 00 40 00 00 02 65 0C
					39 00 00 40 00 00 05 D5 77 77 77 77
					15 00 00 40 00 00 02 65 0C
					39 00 00 40 00 00 05 D7 77 77 77 77
					39 00 00 40 00 00 0E D2 04 01 03 04 0B 0B 0B 0B 0B 00 0E E0 00
					15 00 00 40 00 00 02 D0 11
					/*FIX TE ON*/
					39 00 00 40 00 00 03 F0 AA 10
					15 00 00 00 00 00 02 CF 09
				];
				qcom,mdss-dsi-timing-switch-command-state = "dsi_lp_mode";

				qcom,mdss-dsi-nolp-command = [
					05 00 00 40 00 00 01 38
					/* Frequency Select 120Hz */
					15 00 00 40 00 00 02 6C 00
					15 00 00 40 00 00 02 71 00
					15 00 00 40 00 00 02 75 01
					39 00 00 40 00 00 03 F0 AA 1B
					15 00 00 40 00 00 02 65 0C
					39 00 00 40 00 00 05 D5 77 77 77 77
					15 00 00 40 00 00 02 65 0C
					39 00 00 40 00 00 05 D7 77 77 77 77
					39 00 00 40 00 00 0E D2 04 01 03 04 0B 0B 0B 0B 0B 00 0E E0 00
					15 00 00 40 00 00 02 D0 11
					39 00 00 40 00 00 03 51 00 00
					/*FIX TE ON*/
					39 00 00 40 00 00 03 F0 AA 10
					15 00 00 00 00 00 02 CF 09
				];
				qcom,mdss-dsi-nolp-command-update = <0x51 11 2>, <0x6C 1 1>;
				qcom,mdss-dsi-nolp-command-state = "dsi_lp_mode";

				mi,mdss-dsi-dc-on-command = [
					15 00 00 00 00 00 02 6C 02
				];
				mi,mdss-dsi-dc-on-command-state = "dsi_lp_mode";
				mi,mdss-dsi-dc-off-command = [
					15 00 00 00 00 00 02 6C 00
				];
				mi,mdss-dsi-dc-off-command-state = "dsi_lp_mode";
			};

			timing@idle_120_to_10hz_index_06 {
				#include "dsi-panel-o3-42-0d-0a-dsc-cmd-common.dtsi"
				cell-index = <6>;
				qcom,mdss-dsi-panel-framerate = <120>;
				/* ---------------------------- */
 				/* | 15 - 14 | 13 - 7 | 6 - 0 | */
 				/* ---------------------------- */
 				/* |   mode  | sf fps | min fps| */
 				/* ---------------------------- -*/
 				/* mode: 1 idle, 2 auto, 3 qsync */
 				/*   1 << 14 | 120 << 7 | 10     */
 				qcom,mdss-dsi-h-sync-skew = <31754>;
 				/* mode: 0 normal, 1 idle, 2 auto, 3 qsync, 4 diff, 5 test */
 				mi,mdss-dsi-ddic-mode = "idle";
 				mi,mdss-dsi-sf-framerate = <120>;
 				mi,mdss-dsi-ddic-min-framerate = <10>;
				qcom,dsi-mode-te-width-us = <245>;

				mi,mdss-dc-status-control-dc-6C-cfg = <0x02 0x00>;
				qcom,mdss-dsi-on-command = [
					/*ELVSS DIM OFF*/
					39 00 00 40 00 00 03 F0 AA 10
					15 00 00 40 00 00 02 65 01
					15 00 00 40 00 00 02 D0 05
					15 00 00 40 00 00 02 03 01
					/*TE ON*/
					15 00 00 40 00 00 02 35 00
					/*brightness control*/
					15 00 00 40 00 00 02 53 28
					39 00 00 40 00 00 03 F0 AA 13
					15 00 00 40 00 00 02 C8 10
					15 00 00 40 00 00 02 D0 10
					15 00 00 40 00 00 02 E0 10
					15 00 00 40 00 00 02 E8 10
					39 00 00 40 00 00 03 51 00 00
					15 00 00 40 00 00 02 5E 00
					/*Demura on*/
					15 00 00 40 00 00 02 59 09
					//AGC
					39 00 00 40 00 00 03 FF 5A 81
					15 00 00 40 00 00 02 65 1B
					15 00 00 40 00 00 02 F8 04
					15 00 00 40 00 00 02 65 1A
					15 00 00 40 00 00 02 F8 0F
					15 00 00 40 00 00 02 65 0A
					15 00 00 00 00 00 02 F8 FB
					/* Frequency Select 120Hz */
					15 00 00 40 00 00 02 6C 00
					15 00 00 40 00 00 02 71 00
					15 00 00 40 00 00 02 75 01
					39 00 00 40 00 00 03 F0 AA 1B
					15 00 00 40 00 00 02 65 0C
					39 00 00 40 00 00 05 D5 0B 0B 0B 0B
					15 00 00 40 00 00 02 65 0C
					39 00 00 40 00 00 05 D7 0B 0B 0B 0B
					39 00 00 40 00 00 0E D2 02 01 03 04 0B 07 09 0B 00 00 00 00 00
					15 00 00 40 00 00 02 D0 11
					/*page 11*/
					39 00 00 40 00 00 03 F0 AA 1B
					/*Frame skip OFF*/
					15 00 00 40 00 00 02 D0 00
					/*FIX TE ON*/
					39 00 00 40 00 00 03 F0 AA 10
 					15 00 00 00 00 00 02 CF 09
					/*AOD1*/
					15 00 00 40 00 00 02 6D 00
					15 00 00 40 00 00 02 6F 02
					/*ANRF*/
					15 00 00 40 00 00 02 75 00
					/*PMIC1*/
					15 00 00 40 00 00 02 72 00
					/*PPS*/
					39 00 00 00 00 00 60 70 12 00 00 AB 21 00 0A 6E 04
							B0 00 1E 02 58 02 58 01 55 01
							D2 00 0A 01 88 00 32 00 0D 03
							97 11 48 08 00 0C 00 07 10 20
							00 06 0F 0F 33 0E 1C 2A 38 46
							54 62 69 70 77 79 7B 7D 7E 00
							82 11 40 19 C0 22 3E 32 7C 3A
							BA 3A F8 3B 38 3B 38 3B 76 4B
							76 4B 74 4B 74 5B B4 73 F4 01
							00 00 00 00 00 00
					/*Line1:RGBG Line2:BGRG*/
					39 00 00 40 00 00 03 F0 AA 10
					39 00 00 40 00 00 0E BD 10 02 31 46 75 8A B9 01 32 45 76 89 BA
					/*IC SPR OFF  AP SPR ON*/
					39 00 00 40 00 00 03 F0 AA 17
					15 00 00 40 00 00 02 B0 11
					39 00 00 40 00 00 07 C0 21 00 34 20 31 04
					15 00 00 40 00 00 02 65 06
					15 00 00 40 00 00 02 BF FF
					39 00 00 40 00 00 03 FF 5A 80
					15 00 00 40 00 00 02 65 0A
					39 00 00 40 00 00 03 F9 9E 8F
					15 00 00 40 00 00 02 65 0F
					15 00 00 40 00 00 02 F9 14
					/*optimize high load*/
					39 00 00 40 00 00 03 ff 5A 81
					15 00 00 40 00 00 02 65 03
					15 00 00 40 00 00 02 F3 24
					15 00 00 40 00 00 02 65 05
					15 00 00 40 00 00 02 F3 A0
					/*VREFP power on sequence*/
					39 00 00 40 00 00 03 FF 5A 81
					15 00 00 40 00 00 02 65 02
					39 00 00 40 00 00 05 FB D3 D3 D3 D3
					/*Active Low,ERR High*/
					39 00 00 40 00 00 03 F0 AA 10
					15 00 00 40 00 00 02 65 01
					15 00 00 00 00 00 02 CF 07
					//tp vsync
					39 00 00 40 00 00 03 F0 AA 10
					15 00 00 40 00 00 02 65 03
					15 00 00 00 00 00 02 CF 24
					/*AOD use PMIC Supply*/
					39 00 00 40 00 00 03 F0 AA 10
					15 00 00 40 00 00 02 B6 00
					//SRAM ECC by V Clear
					39 00 00 40 00 00 03 FF 5A 82
					15 00 00 40 00 00 02 65 04
					15 00 00 00 00 00 02 F8 10
					/*ACL*/
					39 00 00 40 00 00 03 F0 AA 11
					15 00 00 40 00 00 02 C0 00
					15 00 00 40 00 00 02 65 09
					39 00 00 40 00 00 04 C0 55 AA AA
					39 00 00 40 00 00 0C C1 03 34 03 99 03 34 03 FF FF A6 00
					15 00 00 40 00 00 02 55 01
					//open PMIC FD open DIC FD
					39 00 00 40 00 00 03 F0 AA 10
					15 00 00 40 00 00 02 65 07
					15 00 00 40 00 00 02 D0 00
					15 00 00 40 00 00 02 65 09
					39 00 00 40 00 00 03 D0 03 19
					15 00 00 40 00 00 02 65 0C
					15 00 00 40 00 00 02 D0 00
					15 00 00 40 00 00 02 65 0E
					39 00 00 40 00 00 03 D0 03 19
					15 00 00 40 00 00 02 65 11
					15 00 00 40 00 00 02 D0 19
					39 00 00 40 00 00 03 F0 AA 12
					15 00 00 40 00 00 02 65 0B
					15 00 00 40 00 00 02 D2 10
					39 00 00 40 00 00 03 F0 AA 10
					39 00 00 00 00 00 09 C4 34 34 34 34 34 34 34 34
					/* Display On */
					05 00 00 00 78 00 01 11
					05 00 00 00 00 00 01 29
				];
				qcom,mdss-dsi-on-command-state = "dsi_lp_mode";

				mi,mdss-dsi-timing-switch-from-auto-mode-command = [
					//AUTO 120HZ 10HZ 1HZ 30HZ
					/*Frame skip OFF (Auto Mode)*/
					15 00 00 40 00 00 02 71 00
					/* Frequency Select 120Hz */
					15 00 00 40 00 00 02 6C 00
					/* Auto Dimming OFF */
					39 00 00 40 00 00 03 F0 AA 1B
					/*Frame skip OFF (Auto Mode)*/
					15 00 00 40 00 00 02 D0 00
					/*Frame Skip Mode 1*/
					15 00 00 00 0A 00 02 75 00
				];
				mi,mdss-dsi-timing-switch-from-auto-mode-command-update = <0x6C 1 1>;
				mi,mdss-dsi-timing-switch-from-auto-mode-command-state = "dsi_lp_mode";

				mi,mdss-dsi-timing-switch-from-skip-mode-command = [
					//FORM 60HZ 40HZ
					/*Frame skip OFF (Auto Mode)*/
					15 00 00 40 00 00 02 71 00
					/* Frequency Select 120Hz */
					15 00 00 00 0A 00 02 6C 00
				];
				mi,mdss-dsi-timing-switch-from-skip-mode-command-update = <0x6C 1 1>;
				mi,mdss-dsi-timing-switch-from-skip-mode-command-state = "dsi_lp_mode";

				mi,mdss-dsi-timing-switch-from-normal-mode-command = [
					//from 120hz 90hz
					/* Frequency Select 120Hz */
					15 00 00 00 00 00 02 6C 00
				];
				mi,mdss-dsi-timing-switch-from-normal-mode-command-update = <0x6C 0 1>;
				mi,mdss-dsi-timing-switch-from-normal-mode-command-state = "dsi_lp_mode";

				qcom,mdss-dsi-timing-switch-command = [
					/* 120→60→30→24→10 */
					15 00 00 40 00 00 02 71 00
					15 00 00 40 00 00 02 75 01
					39 00 00 40 00 00 03 F0 AA 1B
					15 00 00 40 00 00 02 65 0C
					39 00 00 40 00 00 05 D5 0B 0B 0B 0B
					15 00 00 40 00 00 02 65 0C
					39 00 00 40 00 00 05 D7 0B 0B 0B 0B
					39 00 00 40 00 00 0E D2 02 01 03 04 0B 07 09 0B 00 00 00 00 00
					15 00 00 40 00 00 02 D0 11
					/*FIX TE ON*/
					39 00 00 40 00 00 03 F0 AA 10
					15 00 00 00 00 00 02 CF 09
				];
				qcom,mdss-dsi-timing-switch-command-state = "dsi_lp_mode";

				qcom,mdss-dsi-nolp-command = [
					05 00 00 40 00 00 01 38
					/* Frequency Select 120Hz */
					15 00 00 40 00 00 02 6C 00
					15 00 00 40 00 00 02 71 00
					15 00 00 40 00 00 02 75 01
					39 00 00 40 00 00 03 F0 AA 1B
					15 00 00 40 00 00 02 65 0C
					39 00 00 40 00 00 05 D5 0B 0B 0B 0B
					15 00 00 40 00 00 02 65 0C
					39 00 00 40 00 00 05 D7 0B 0B 0B 0B
					39 00 00 40 00 00 0E D2 02 01 03 04 0B 07 09 0B 00 00 00 00 00
					15 00 00 40 00 00 02 D0 11
					39 00 00 40 00 00 03 51 00 00
					/*FIX TE ON*/
					39 00 00 40 00 00 03 F0 AA 10
					15 00 00 00 00 00 02 CF 09
				];
				qcom,mdss-dsi-nolp-command-update = <0x51 11 2>, <0x6C 1 1>;
				qcom,mdss-dsi-nolp-command-state = "dsi_lp_mode";

				mi,mdss-dsi-dc-on-command = [
					15 00 00 00 00 00 02 6C 02
				];
				mi,mdss-dsi-dc-on-command-state = "dsi_lp_mode";
				mi,mdss-dsi-dc-off-command = [
					15 00 00 00 00 00 02 6C 00
				];
				mi,mdss-dsi-dc-off-command-state = "dsi_lp_mode";
			};

			timing@idle_120_to_1hz_index_07 {
				#include "dsi-panel-o3-42-0d-0a-dsc-cmd-common.dtsi"
				cell-index = <7>;
				qcom,mdss-dsi-panel-framerate = <120>;
				/* ---------------------------- */
				/* | 15 - 14 | 13 - 7 | 6 - 0 | */
				/* ---------------------------- */
				/* |   mode  | sf fps | min fps| */
				/* ---------------------------- -*/
				/* mode: 1 idle, 2 auto, 3 qsync */
				/*   1 << 14 | 120 << 7 | 1     */
				qcom,mdss-dsi-h-sync-skew = <31745>;
				mi,mdss-dc-status-control-dc-6C-cfg = <0x02 0x00>;
				mi,mdss-dsi-ddic-mode = "idle";
				mi,mdss-dsi-sf-framerate = <120>;
				mi,mdss-dsi-ddic-min-framerate = <1>;
				qcom,dsi-mode-te-width-us = <245>;

				qcom,mdss-dsi-on-command = [
					/*ELVSS DIM OFF*/
					39 00 00 40 00 00 03 F0 AA 10
					15 00 00 40 00 00 02 65 01
					15 00 00 40 00 00 02 D0 05
					15 00 00 40 00 00 02 03 01
					/*TE ON*/
					15 00 00 40 00 00 02 35 00
					/*brightness control*/
					15 00 00 40 00 00 02 53 28
					39 00 00 40 00 00 03 F0 AA 13
					15 00 00 40 00 00 02 C8 10
					15 00 00 40 00 00 02 D0 10
					15 00 00 40 00 00 02 E0 10
					15 00 00 40 00 00 02 E8 10
					39 00 00 40 00 00 03 51 00 00
					15 00 00 40 00 00 02 5E 00
					/*Demura on*/
					15 00 00 40 00 00 02 59 09
					//AGC
					39 00 00 40 00 00 03 FF 5A 81
					15 00 00 40 00 00 02 65 1B
					15 00 00 40 00 00 02 F8 04
					15 00 00 40 00 00 02 65 1A
					15 00 00 40 00 00 02 F8 0F
					15 00 00 40 00 00 02 65 0A
					15 00 00 00 00 00 02 F8 FB
					/* Frequency Select 120Hz */
					15 00 00 40 00 00 02 6C 00
					15 00 00 40 00 00 02 71 00
					15 00 00 40 00 00 02 75 01
					39 00 00 40 00 00 03 F0 AA 1B
					15 00 00 40 00 00 02 65 0C
					39 00 00 40 00 00 05 D5 77 77 77 77
					15 00 00 40 00 00 02 65 0C
					39 00 00 40 00 00 05 D7 77 77 77 77
					39 00 00 40 00 00 0E D2 04 01 03 04 0B 0B 0B 0B 0B 00 0E E0 00
					15 00 00 40 00 00 02 D0 11
					/*page 11*/
					39 00 00 40 00 00 03 F0 AA 1B
					/*Frame skip OFF*/
					15 00 00 40 00 00 02 D0 00
					/*FIX TE ON*/
					39 00 00 40 00 00 03 F0 AA 10
 					15 00 00 00 00 00 02 CF 09
					/*AOD1*/
					15 00 00 40 00 00 02 6D 00
					15 00 00 40 00 00 02 6F 02
					/*ANRF*/
					15 00 00 40 00 00 02 75 00
					/*PMIC1*/
					15 00 00 40 00 00 02 72 00
					/*PPS*/
					39 00 00 00 00 00 60 70 12 00 00 AB 21 00 0A 6E 04
							B0 00 1E 02 58 02 58 01 55 01
							D2 00 0A 01 88 00 32 00 0D 03
							97 11 48 08 00 0C 00 07 10 20
							00 06 0F 0F 33 0E 1C 2A 38 46
							54 62 69 70 77 79 7B 7D 7E 00
							82 11 40 19 C0 22 3E 32 7C 3A
							BA 3A F8 3B 38 3B 38 3B 76 4B
							76 4B 74 4B 74 5B B4 73 F4 01
							00 00 00 00 00 00
					/*Line1:RGBG Line2:BGRG*/
					39 00 00 40 00 00 03 F0 AA 10
					39 00 00 40 00 00 0E BD 10 02 31 46 75 8A B9 01 32 45 76 89 BA
					/*IC SPR OFF  AP SPR ON*/
					39 00 00 40 00 00 03 F0 AA 17
					15 00 00 40 00 00 02 B0 11
					39 00 00 40 00 00 07 C0 21 00 34 20 31 04
					15 00 00 40 00 00 02 65 06
					15 00 00 40 00 00 02 BF FF
					39 00 00 40 00 00 03 FF 5A 80
					15 00 00 40 00 00 02 65 0A
					39 00 00 40 00 00 03 F9 9E 8F
					15 00 00 40 00 00 02 65 0F
					15 00 00 40 00 00 02 F9 14
					/*optimize high load*/
					39 00 00 40 00 00 03 ff 5A 81
					15 00 00 40 00 00 02 65 03
					15 00 00 40 00 00 02 F3 24
					15 00 00 40 00 00 02 65 05
					15 00 00 40 00 00 02 F3 A0
					/*VREFP power on sequence*/
					39 00 00 40 00 00 03 FF 5A 81
					15 00 00 40 00 00 02 65 02
					39 00 00 40 00 00 05 FB D3 D3 D3 D3
					/*Active Low,ERR High*/
					39 00 00 40 00 00 03 F0 AA 10
					15 00 00 40 00 00 02 65 01
					15 00 00 00 00 00 02 CF 07
					//tp vsync
					39 00 00 40 00 00 03 F0 AA 10
					15 00 00 40 00 00 02 65 03
					15 00 00 00 00 00 02 CF 24
					/*AOD use PMIC Supply*/
					39 00 00 40 00 00 03 F0 AA 10
					15 00 00 40 00 00 02 B6 00
					//SRAM ECC by V Clear
					39 00 00 40 00 00 03 FF 5A 82
					15 00 00 40 00 00 02 65 04
					15 00 00 00 00 00 02 F8 10
					/*ACL*/
					39 00 00 40 00 00 03 F0 AA 11
					15 00 00 40 00 00 02 C0 00
					15 00 00 40 00 00 02 65 09
					39 00 00 40 00 00 04 C0 55 AA AA
					39 00 00 40 00 00 0C C1 03 34 03 99 03 34 03 FF FF A6 00
					15 00 00 40 00 00 02 55 01
					//open PMIC FD open DIC FD
					39 00 00 40 00 00 03 F0 AA 10
					15 00 00 40 00 00 02 65 07
					15 00 00 40 00 00 02 D0 00
					15 00 00 40 00 00 02 65 09
					39 00 00 40 00 00 03 D0 03 19
					15 00 00 40 00 00 02 65 0C
					15 00 00 40 00 00 02 D0 00
					15 00 00 40 00 00 02 65 0E
					39 00 00 40 00 00 03 D0 03 19
					15 00 00 40 00 00 02 65 11
					15 00 00 40 00 00 02 D0 19
					39 00 00 40 00 00 03 F0 AA 12
					15 00 00 40 00 00 02 65 0B
					15 00 00 40 00 00 02 D2 10
					39 00 00 40 00 00 03 F0 AA 10
					39 00 00 00 00 00 09 C4 34 34 34 34 34 34 34 34
					/* Display On */
					05 00 00 00 78 00 01 11
					05 00 00 00 00 00 01 29
				];
				qcom,mdss-dsi-on-command-state = "dsi_lp_mode";

				mi,mdss-dsi-timing-switch-from-auto-mode-command = [
					//AUTO 120HZ 10HZ 1HZ 30HZ
					/*Frame skip OFF (Auto Mode)*/
					15 00 00 40 00 00 02 71 00
					/* Frequency Select 120Hz */
					15 00 00 40 00 00 02 6C 00
					/* Auto Dimming OFF */
					39 00 00 40 00 00 03 F0 AA 1B
					/*Frame skip OFF (Auto Mode)*/
					15 00 00 40 00 00 02 D0 00
					/*Frame Skip Mode 1*/
					15 00 00 00 0A 00 02 75 00
				];
				mi,mdss-dsi-timing-switch-from-auto-mode-command-update = <0x6C 1 1>;
				mi,mdss-dsi-timing-switch-from-auto-mode-command-state = "dsi_lp_mode";

				mi,mdss-dsi-timing-switch-from-skip-mode-command = [
					//FORM 60HZ 40HZ
					/*Frame skip OFF (Auto Mode)*/
					15 00 00 40 00 00 02 71 00
					/* Frequency Select 120Hz */
					15 00 00 00 0A 00 02 6C 00
				];
				mi,mdss-dsi-timing-switch-from-skip-mode-command-update = <0x6C 1 1>;
				mi,mdss-dsi-timing-switch-from-skip-mode-command-state = "dsi_lp_mode";

				mi,mdss-dsi-timing-switch-from-normal-mode-command = [
					//from 120hz 90hz
					/* Frequency Select 120Hz */
					15 00 00 00 00 00 02 6C 00
				];
				mi,mdss-dsi-timing-switch-from-normal-mode-command-update = <0x6C 0 1>;
				mi,mdss-dsi-timing-switch-from-normal-mode-command-state = "dsi_lp_mode";

				qcom,mdss-dsi-timing-switch-command = [
					/* 120→60→30→24→10*30→1 */
					15 00 00 40 00 00 02 71 00
					15 00 00 40 00 00 02 75 01
					39 00 00 40 00 00 03 F0 AA 1B
					15 00 00 40 00 00 02 65 0C
					39 00 00 40 00 00 05 D5 77 77 77 77
					15 00 00 40 00 00 02 65 0C
					39 00 00 40 00 00 05 D7 77 77 77 77
					39 00 00 40 00 00 0E D2 04 01 03 04 0B 0B 0B 0B 0B 00 0E E0 00
					15 00 00 40 00 00 02 D0 11
					/*FIX TE ON*/
					39 00 00 40 00 00 03 F0 AA 10
					15 00 00 00 00 00 02 CF 09
				];
				qcom,mdss-dsi-timing-switch-command-state = "dsi_lp_mode";

				qcom,mdss-dsi-nolp-command = [
					05 00 00 40 00 00 01 38
					/* Frequency Select 120Hz */
					15 00 00 40 00 00 02 6C 00
					15 00 00 40 00 00 02 71 00
					15 00 00 40 00 00 02 75 01
					39 00 00 40 00 00 03 F0 AA 1B
					15 00 00 40 00 00 02 65 0C
					39 00 00 40 00 00 05 D5 77 77 77 77
					15 00 00 40 00 00 02 65 0C
					39 00 00 40 00 00 05 D7 77 77 77 77
					39 00 00 40 00 00 0E D2 04 01 03 04 0B 0B 0B 0B 0B 00 0E E0 00
					15 00 00 40 00 00 02 D0 11
					39 00 00 40 00 00 03 51 00 00
					/*FIX TE ON*/
					39 00 00 40 00 00 03 F0 AA 10
					15 00 00 00 00 00 02 CF 09
				];
				qcom,mdss-dsi-nolp-command-update = <0x51 11 2>, <0x6C 1 1>;
				qcom,mdss-dsi-nolp-command-state = "dsi_lp_mode";

				mi,mdss-dsi-dc-on-command = [
					15 00 00 00 00 00 02 6C 02
				];
				mi,mdss-dsi-dc-on-command-state = "dsi_lp_mode";
				mi,mdss-dsi-dc-off-command = [
					15 00 00 00 00 00 02 6C 00
				];
				mi,mdss-dsi-dc-off-command-state = "dsi_lp_mode";
			};

			timing@normal_90hz_index_08 {
				#include "dsi-panel-o3-42-0d-0a-dsc-cmd-common.dtsi"
				cell-index = <8>;
				qcom,mdss-dsi-panel-framerate = <90>;
				qcom,mdss-dsi-h-sync-skew = <0>;
				mi,mdss-dc-status-control-dc-6C-cfg = <0x03 0x01>;
				qcom,dsi-mode-te-width-us = <3100>;

				qcom,mdss-dsi-on-command = [
					/*ELVSS DIM OFF*/
					39 00 00 40 00 00 03 F0 AA 10
					15 00 00 40 00 00 02 65 01
					15 00 00 40 00 00 02 D0 05
					15 00 00 40 00 00 02 03 01
					/*TE ON*/
					15 00 00 40 00 00 02 35 00
					/*brightness control*/
					15 00 00 40 00 00 02 53 28
					39 00 00 40 00 00 03 F0 AA 13
					15 00 00 40 00 00 02 C8 10
					15 00 00 40 00 00 02 D0 10
					15 00 00 40 00 00 02 E0 10
					15 00 00 40 00 00 02 E8 10
					39 00 00 40 00 00 03 51 00 00
					15 00 00 40 00 00 02 5E 00
					/*Demura on*/
					15 00 00 40 00 00 02 59 09
					//AGC
					39 00 00 40 00 00 03 FF 5A 81
					15 00 00 40 00 00 02 65 1B
					15 00 00 40 00 00 02 F8 04
					15 00 00 40 00 00 02 65 1A
					15 00 00 40 00 00 02 F8 0F
					15 00 00 40 00 00 02 65 0A
					15 00 00 00 00 00 02 F8 FB
					/* Auto Dimming OFF */
					39 00 00 40 00 00 03 F0 AA 1B
					/*Frame skip OFF (Auto Mode)*/
					15 00 00 40 00 00 02 D0 00
					/*Frame Skip Mode 1*/
					15 00 00 00 00 00 02 75 00
					/*90hz normal*/
					15 00 00 40 00 00 02 6C 01
					/*FIX TE OFF*/
					39 00 00 40 00 00 03 F0 AA 10
 					15 00 00 00 00 00 02 CF 16
					/*AOD1*/
					15 00 00 40 00 00 02 6D 00
					15 00 00 40 00 00 02 6F 02
					/*ANRF*/
					15 00 00 40 00 00 02 75 00
					/*PMIC1*/
					15 00 00 40 00 00 02 72 00
					/*PPS*/
					39 00 00 00 00 00 60 70 12 00 00 AB 21 00 0A 6E 04
							B0 00 1E 02 58 02 58 01 55 01
							D2 00 0A 01 88 00 32 00 0D 03
							97 11 48 08 00 0C 00 07 10 20
							00 06 0F 0F 33 0E 1C 2A 38 46
							54 62 69 70 77 79 7B 7D 7E 00
							82 11 40 19 C0 22 3E 32 7C 3A
							BA 3A F8 3B 38 3B 38 3B 76 4B
							76 4B 74 4B 74 5B B4 73 F4 01
							00 00 00 00 00 00
					/*Line1:RGBG Line2:BGRG*/
					39 00 00 40 00 00 03 F0 AA 10
					39 00 00 40 00 00 0E BD 10 02 31 46 75 8A B9 01 32 45 76 89 BA
					/*IC SPR OFF  AP SPR ON*/
					39 00 00 40 00 00 03 F0 AA 17
					15 00 00 40 00 00 02 B0 11
					39 00 00 40 00 00 07 C0 21 00 34 20 31 04
					15 00 00 40 00 00 02 65 06
					15 00 00 40 00 00 02 BF FF
					39 00 00 40 00 00 03 FF 5A 80
					15 00 00 40 00 00 02 65 0A
					39 00 00 40 00 00 03 F9 9E 8F
					15 00 00 40 00 00 02 65 0F
					15 00 00 40 00 00 02 F9 14
					/*optimize high load*/
					39 00 00 40 00 00 03 ff 5A 81
					15 00 00 40 00 00 02 65 03
					15 00 00 40 00 00 02 F3 24
					15 00 00 40 00 00 02 65 05
					15 00 00 40 00 00 02 F3 A0
					/*VREFP power on sequence*/
					39 00 00 40 00 00 03 FF 5A 81
					15 00 00 40 00 00 02 65 02
					39 00 00 40 00 00 05 FB D3 D3 D3 D3
					/*Active Low,ERR High*/
					39 00 00 40 00 00 03 F0 AA 10
					15 00 00 40 00 00 02 65 01
					15 00 00 00 00 00 02 CF 07
					//tp vsync
					39 00 00 40 00 00 03 F0 AA 10
					15 00 00 40 00 00 02 65 03
					15 00 00 00 00 00 02 CF 24
					/*AOD use PMIC Supply*/
					39 00 00 40 00 00 03 F0 AA 10
					15 00 00 40 00 00 02 B6 00
					//SRAM ECC by V Clear
					39 00 00 40 00 00 03 FF 5A 82
					15 00 00 40 00 00 02 65 04
					15 00 00 00 00 00 02 F8 10
					/*ACL*/
					39 00 00 40 00 00 03 F0 AA 11
					15 00 00 40 00 00 02 C0 00
					15 00 00 40 00 00 02 65 09
					39 00 00 40 00 00 04 C0 55 AA AA
					39 00 00 40 00 00 0C C1 03 34 03 99 03 34 03 FF FF A6 00
					15 00 00 40 00 00 02 55 01
					//open PMIC FD open DIC FD
					39 00 00 40 00 00 03 F0 AA 10
					15 00 00 40 00 00 02 65 07
					15 00 00 40 00 00 02 D0 00
					15 00 00 40 00 00 02 65 09
					39 00 00 40 00 00 03 D0 03 19
					15 00 00 40 00 00 02 65 0C
					15 00 00 40 00 00 02 D0 00
					15 00 00 40 00 00 02 65 0E
					39 00 00 40 00 00 03 D0 03 19
					15 00 00 40 00 00 02 65 11
					15 00 00 40 00 00 02 D0 19
					39 00 00 40 00 00 03 F0 AA 12
					15 00 00 40 00 00 02 65 0B
					15 00 00 40 00 00 02 D2 10
					39 00 00 40 00 00 03 F0 AA 10
					39 00 00 00 00 00 09 C4 34 34 34 34 34 34 34 34
					/* Display On */
					05 00 00 00 78 00 01 11
					05 00 00 00 00 00 01 29
				];
				qcom,mdss-dsi-on-command-state = "dsi_lp_mode";

				qcom,mdss-dsi-timing-switch-command = [
					/* Auto Dimming OFF */
					39 00 00 40 00 00 03 F0 AA 1B
					/*Frame skip OFF (Auto Mode)*/
					15 00 00 40 00 00 02 D0 00
					/*Frame Skip Mode 1*/
					15 00 00 40 00 00 02 75 00
					/*90HZ*/
					15 00 00 40 00 00 02 6C 01
					15 00 00 40 00 00 02 71 00
					/*FIX TE OFF*/
					39 00 00 40 00 00 03 F0 AA 10
					15 00 00 00 00 00 02 CF 16
				];
				qcom,mdss-dsi-timing-switch-command-update = <0x6C 3 1>;
				qcom,mdss-dsi-timing-switch-command-state = "dsi_lp_mode";

				qcom,mdss-dsi-nolp-command = [
					05 00 00 40 00 00 01 38
					15 00 00 40 00 00 02 75 00
					39 00 00 40 00 00 03 F0 AA 1B
					15 00 00 40 00 00 02 D0 00
					39 00 00 40 00 00 03 51 00 00
					/*FIX TE OFF*/
					39 00 00 40 00 00 03 F0 AA 10
					15 00 00 00 09 00 02 CF 16
					/*90HZ*/
					15 00 00 40 00 00 02 6C 01
					15 00 00 00 00 00 02 71 00
				];
				qcom,mdss-dsi-nolp-command-update = <0x51 4 2>, <0x6C 7 1>;
				qcom,mdss-dsi-nolp-command-state = "dsi_lp_mode";

				mi,mdss-dsi-dc-on-command = [
					15 00 00 00 00 00 02 6C 03
				];
				mi,mdss-dsi-dc-on-command-state = "dsi_lp_mode";
				mi,mdss-dsi-dc-off-command = [
					15 00 00 00 00 00 02 6C 01
				];
				mi,mdss-dsi-dc-off-command-state = "dsi_lp_mode";
			};

			timing@auto_120_to_10hz_index_09 {
				#include "dsi-panel-o3-42-0d-0a-dsc-cmd-common.dtsi"
				cell-index = <9>;
				qcom,mdss-dsi-panel-framerate = <120>;
				/* ---------------------------- */
				/* | 15 - 14 | 13 - 7 | 6 - 0 | */
				/* ---------------------------- */
				/* |   mode  | sf fps | min fps| */
				/* ---------------------------- -*/
				/* mode: 1 idle, 2 auto, 3 qsync */
				/*   2 << 14 | 120 << 7 | 10*/
				qcom,mdss-dsi-h-sync-skew = <48138>;
				mi,mdss-dsi-ddic-mode = "auto";
				mi,mdss-dsi-sf-framerate = <120>;
				mi,mdss-dsi-ddic-min-framerate = <10>;
				mi,mdss-dc-status-control-dc-6C-cfg = <0x02 0x00>;
				qcom,dsi-mode-te-width-us = <245>;

				qcom,mdss-dsi-on-command = [
					/*ELVSS DIM OFF*/
					39 00 00 40 00 00 03 F0 AA 10
					15 00 00 40 00 00 02 65 01
					15 00 00 40 00 00 02 D0 05
					15 00 00 40 00 00 02 03 01
					/*TE ON*/
					15 00 00 40 00 00 02 35 00
					/*brightness control*/
					15 00 00 40 00 00 02 53 28
					39 00 00 40 00 00 03 F0 AA 13
					15 00 00 40 00 00 02 C8 10
					15 00 00 40 00 00 02 D0 10
					15 00 00 40 00 00 02 E0 10
					15 00 00 40 00 00 02 E8 10
					39 00 00 40 00 00 03 51 00 00
					15 00 00 40 00 00 02 5E 00
					/*Demura on*/
					15 00 00 40 00 00 02 59 09
					//AGC
					39 00 00 40 00 00 03 FF 5A 81
					15 00 00 40 00 00 02 65 1B
					15 00 00 40 00 00 02 F8 04
					15 00 00 40 00 00 02 65 1A
					15 00 00 40 00 00 02 F8 0F
					15 00 00 40 00 00 02 65 0A
					15 00 00 00 00 00 02 F8 FB
					/* Frequency Select 120Hz */
					15 00 00 40 00 00 02 6C 00
					15 00 00 40 00 00 02 71 00
					15 00 00 40 00 00 02 75 01
					39 00 00 40 00 00 03 F0 AA 1B
					15 00 00 40 00 00 02 65 0C
					39 00 00 40 00 00 05 D5 0B 0B 0B 0B
					15 00 00 40 00 00 02 65 0C
					39 00 00 40 00 00 05 D7 0B 0B 0B 0B
					39 00 00 40 00 00 0E D2 02 01 03 04 0B 07 09 0B 00 00 00 00 00
					15 00 00 40 00 00 02 D0 11
					/*page 11*/
					39 00 00 40 00 00 03 F0 AA 1B
					/*Frame skip OFF*/
					15 00 00 40 00 00 02 D0 00
					/*FIX TE ON*/
					39 00 00 40 00 00 03 F0 AA 10
 					15 00 00 00 00 00 02 CF 09
					/*AOD1*/
					15 00 00 40 00 00 02 6D 00
					15 00 00 40 00 00 02 6F 02
					/*ANRF*/
					15 00 00 40 00 00 02 75 00
					/*PMIC1*/
					15 00 00 40 00 00 02 72 00
					/*PPS*/
					39 00 00 00 00 00 60 70 12 00 00 AB 21 00 0A 6E 04
							B0 00 1E 02 58 02 58 01 55 01
							D2 00 0A 01 88 00 32 00 0D 03
							97 11 48 08 00 0C 00 07 10 20
							00 06 0F 0F 33 0E 1C 2A 38 46
							54 62 69 70 77 79 7B 7D 7E 00
							82 11 40 19 C0 22 3E 32 7C 3A
							BA 3A F8 3B 38 3B 38 3B 76 4B
							76 4B 74 4B 74 5B B4 73 F4 01
							00 00 00 00 00 00
					/*Line1:RGBG Line2:BGRG*/
					39 00 00 40 00 00 03 F0 AA 10
					39 00 00 40 00 00 0E BD 10 02 31 46 75 8A B9 01 32 45 76 89 BA
					/*IC SPR OFF  AP SPR ON*/
					39 00 00 40 00 00 03 F0 AA 17
					15 00 00 40 00 00 02 B0 11
					39 00 00 40 00 00 07 C0 21 00 34 20 31 04
					15 00 00 40 00 00 02 65 06
					15 00 00 40 00 00 02 BF FF
					39 00 00 40 00 00 03 FF 5A 80
					15 00 00 40 00 00 02 65 0A
					39 00 00 40 00 00 03 F9 9E 8F
					15 00 00 40 00 00 02 65 0F
					15 00 00 40 00 00 02 F9 14
					/*optimize high load*/
					39 00 00 40 00 00 03 ff 5A 81
					15 00 00 40 00 00 02 65 03
					15 00 00 40 00 00 02 F3 24
					15 00 00 40 00 00 02 65 05
					15 00 00 40 00 00 02 F3 A0
					/*VREFP power on sequence*/
					39 00 00 40 00 00 03 FF 5A 81
					15 00 00 40 00 00 02 65 02
					39 00 00 40 00 00 05 FB D3 D3 D3 D3
					/*Active Low,ERR High*/
					39 00 00 40 00 00 03 F0 AA 10
					15 00 00 40 00 00 02 65 01
					15 00 00 00 00 00 02 CF 07
					//tp vsync
					39 00 00 40 00 00 03 F0 AA 10
					15 00 00 40 00 00 02 65 03
					15 00 00 00 00 00 02 CF 24
					/*AOD use PMIC Supply*/
					39 00 00 40 00 00 03 F0 AA 10
					15 00 00 40 00 00 02 B6 00
					//SRAM ECC by V Clear
					39 00 00 40 00 00 03 FF 5A 82
					15 00 00 40 00 00 02 65 04
					15 00 00 00 00 00 02 F8 10
					/*ACL*/
					39 00 00 40 00 00 03 F0 AA 11
					15 00 00 40 00 00 02 C0 00
					15 00 00 40 00 00 02 65 09
					39 00 00 40 00 00 04 C0 55 AA AA
					39 00 00 40 00 00 0C C1 03 34 03 99 03 34 03 FF FF A6 00
					15 00 00 40 00 00 02 55 01
					//open PMIC FD open DIC FD
					39 00 00 40 00 00 03 F0 AA 10
					15 00 00 40 00 00 02 65 07
					15 00 00 40 00 00 02 D0 00
					15 00 00 40 00 00 02 65 09
					39 00 00 40 00 00 03 D0 03 19
					15 00 00 40 00 00 02 65 0C
					15 00 00 40 00 00 02 D0 00
					15 00 00 40 00 00 02 65 0E
					39 00 00 40 00 00 03 D0 03 19
					15 00 00 40 00 00 02 65 11
					15 00 00 40 00 00 02 D0 19
					39 00 00 40 00 00 03 F0 AA 12
					15 00 00 40 00 00 02 65 0B
					15 00 00 40 00 00 02 D2 10
					39 00 00 40 00 00 03 F0 AA 10
					39 00 00 00 00 00 09 C4 34 34 34 34 34 34 34 34
					/* Display On */
					05 00 00 00 78 00 01 11
					05 00 00 00 00 00 01 29
				];
				qcom,mdss-dsi-on-command-state = "dsi_lp_mode";

				mi,mdss-dsi-timing-switch-from-auto-mode-command = [
					//AUTO 120HZ 10HZ 1HZ 30HZ
					/*Frame skip OFF (Auto Mode)*/
					15 00 00 40 00 00 02 71 00
					/* Frequency Select 120Hz */
					15 00 00 40 00 00 02 6C 00
					/* Auto Dimming OFF */
					39 00 00 40 00 00 03 F0 AA 1B
					/*Frame skip OFF (Auto Mode)*/
					15 00 00 40 00 00 02 D0 00
					/*Frame Skip Mode 1*/
					15 00 00 00 0A 00 02 75 00
				];
				mi,mdss-dsi-timing-switch-from-auto-mode-command-update = <0x6C 1 1>;
				mi,mdss-dsi-timing-switch-from-auto-mode-command-state = "dsi_lp_mode";

				mi,mdss-dsi-timing-switch-from-skip-mode-command = [
					//FORM 60HZ 40HZ
					/*Frame skip OFF (Auto Mode)*/
					15 00 00 40 00 00 02 71 00
					/* Frequency Select 120Hz */
					15 00 00 00 0A 00 02 6C 00
				];
				mi,mdss-dsi-timing-switch-from-skip-mode-command-update = <0x6C 1 1>;
				mi,mdss-dsi-timing-switch-from-skip-mode-command-state = "dsi_lp_mode";

				mi,mdss-dsi-timing-switch-from-normal-mode-command = [
					//from 120hz 90hz
					/* Frequency Select 120Hz */
					15 00 00 00 00 00 02 6C 00
				];
				mi,mdss-dsi-timing-switch-from-normal-mode-command-update = <0x6C 0 1>;
				mi,mdss-dsi-timing-switch-from-normal-mode-command-state = "dsi_lp_mode";

				qcom,mdss-dsi-timing-switch-command = [
					/* 120→60→30→24→10 */
					15 00 00 40 00 00 02 71 00
					15 00 00 40 00 00 02 75 01
					39 00 00 40 00 00 03 F0 AA 1B
					15 00 00 40 00 00 02 65 0C
					39 00 00 40 00 00 05 D5 0B 0B 0B 0B
					15 00 00 40 00 00 02 65 0C
					39 00 00 40 00 00 05 D7 0B 0B 0B 0B
					39 00 00 40 00 00 0E D2 02 01 03 04 0B 07 09 0B 00 00 00 00 00
					15 00 00 40 00 00 02 D0 11
					/*FIX TE ON*/
					39 00 00 40 00 00 03 F0 AA 10
					15 00 00 00 00 00 02 CF 09
				];
				qcom,mdss-dsi-timing-switch-command-state = "dsi_lp_mode";

				qcom,mdss-dsi-nolp-command = [
					05 00 00 40 00 00 01 38
					/* Frequency Select 120Hz */
					15 00 00 40 00 00 02 6C 00
					15 00 00 40 00 00 02 71 00
					15 00 00 40 00 00 02 75 01
					39 00 00 40 00 00 03 F0 AA 1B
					15 00 00 40 00 00 02 65 0C
					39 00 00 40 00 00 05 D5 0B 0B 0B 0B
					15 00 00 40 00 00 02 65 0C
					39 00 00 40 00 00 05 D7 0B 0B 0B 0B
					39 00 00 40 00 00 0E D2 02 01 03 04 0B 07 09 0B 00 00 00 00 00
					15 00 00 40 00 00 02 D0 11
					39 00 00 40 00 00 03 51 00 00
					/*FIX TE ON*/
					39 00 00 40 00 00 03 F0 AA 10
					15 00 00 00 00 00 02 CF 09
				];
				qcom,mdss-dsi-nolp-command-update = <0x51 11 2>, <0x6C 1 1>;
				qcom,mdss-dsi-nolp-command-state = "dsi_lp_mode";

				mi,mdss-dsi-dc-on-command = [
					15 00 00 00 00 00 02 6C 02
				];
				mi,mdss-dsi-dc-on-command-state = "dsi_lp_mode";
				mi,mdss-dsi-dc-off-command = [
					15 00 00 00 00 00 02 6C 00
				];
				mi,mdss-dsi-dc-off-command-state = "dsi_lp_mode";
			};

			timing@wqhd_test_120_to_0.5hz_index_11 {
				#include "dsi-panel-o3-42-0d-0a-dsc-cmd-common.dtsi"
				cell-index = <11>;
				qcom,mdss-dsi-panel-framerate = <120>;
				/* ---------------------------- */
				/* | 15 - 14 | 13 - 7 | 6 - 0 | */
				/* ---------------------------- */
				/* |   mode  | sf fps | min fps| */
				/* ---------------------------- -*/
				/* mode: 1 idle, 2 auto, 3 qsync */
				/*   1 << 14 | 120 << 7 | 127    */
				qcom,mdss-dsi-h-sync-skew = <31871>;
				/* mode: 0 normal, 1 idle, 2 auto, 3 qsync, 4 diff, 5 test */
				mi,mdss-dsi-ddic-mode = "test";
				mi,mdss-dsi-sf-framerate = <120>;
				mi,mdss-dsi-ddic-min-framerate = <127>;
				mi,mdss-dc-status-control-dc-6C-cfg = <0x02 0x00>;

				qcom,mdss-dsi-on-command = [
					/*ELVSS DIM OFF*/
					39 00 00 40 00 00 03 F0 AA 10
					15 00 00 40 00 00 02 65 01
					15 00 00 40 00 00 02 D0 05
					15 00 00 40 00 00 02 03 01
					/*TE ON*/
					15 00 00 40 00 00 02 35 00
					/*brightness control*/
					15 00 00 40 00 00 02 53 28
					39 00 00 40 00 00 03 F0 AA 13
					15 00 00 40 00 00 02 C8 10
					15 00 00 40 00 00 02 D0 10
					15 00 00 40 00 00 02 E0 10
					15 00 00 40 00 00 02 E8 10
					39 00 00 40 00 00 03 51 00 00
					15 00 00 40 00 00 02 5E 00
					/*Demura on*/
					15 00 00 40 00 00 02 59 09
					//AGC
					39 00 00 40 00 00 03 FF 5A 81
					15 00 00 40 00 00 02 65 1B
					15 00 00 40 00 00 02 F8 04
					15 00 00 40 00 00 02 65 1A
					15 00 00 40 00 00 02 F8 0F
					15 00 00 40 00 00 02 65 0A
					15 00 00 00 00 00 02 F8 FB
					/*auto 0.5HZ*/
					15 00 00 40 00 00 02 6C 00
					15 00 00 40 00 00 02 71 00
					15 00 00 40 00 00 02 75 01
					39 00 00 40 00 00 03 F0 AA 1B
					15 00 00 40 00 00 02 65 0C
					39 00 00 40 00 00 05 D5 EF EF EF EF
					39 00 00 40 00 00 0E D2 00 EF 04 03 05 07 09 0B 00 00 00 00 00
					15 00 00 40 00 00 02 D0 11
					/*FIX TE ON*/
					39 00 00 40 00 00 03 F0 AA 10
 					15 00 00 00 00 00 02 CF 09
					/*AOD1*/
					15 00 00 40 00 00 02 6D 00
					15 00 00 40 00 00 02 6F 02
					/*ANRF*/
					15 00 00 40 00 00 02 75 00
					/*PMIC1*/
					15 00 00 40 00 00 02 72 00
					/*PPS*/
					39 00 00 00 00 00 60 70 12 00 00 AB 21 00 0A 6E 04
							B0 00 1E 02 58 02 58 01 55 01
							D2 00 0A 01 88 00 32 00 0D 03
							97 11 48 08 00 0C 00 07 10 20
							00 06 0F 0F 33 0E 1C 2A 38 46
							54 62 69 70 77 79 7B 7D 7E 00
							82 11 40 19 C0 22 3E 32 7C 3A
							BA 3A F8 3B 38 3B 38 3B 76 4B
							76 4B 74 4B 74 5B B4 73 F4 01
							00 00 00 00 00 00
					/*Line1:RGBG Line2:BGRG*/
					39 00 00 40 00 00 03 F0 AA 10
					39 00 00 40 00 00 0E BD 10 02 31 46 75 8A B9 01 32 45 76 89 BA
					/*IC SPR OFF  AP SPR ON*/
					39 00 00 40 00 00 03 F0 AA 17
					15 00 00 40 00 00 02 B0 11
					39 00 00 40 00 00 07 C0 21 00 34 20 31 04
					15 00 00 40 00 00 02 65 06
					15 00 00 40 00 00 02 BF FF
					39 00 00 40 00 00 03 FF 5A 80
					15 00 00 40 00 00 02 65 0A
					39 00 00 40 00 00 03 F9 9E 8F
					15 00 00 40 00 00 02 65 0F
					15 00 00 40 00 00 02 F9 14
					/*optimize high load*/
					39 00 00 40 00 00 03 ff 5A 81
					15 00 00 40 00 00 02 65 03
					15 00 00 40 00 00 02 F3 24
					15 00 00 40 00 00 02 65 05
					15 00 00 40 00 00 02 F3 A0
					/*VREFP power on sequence*/
					39 00 00 40 00 00 03 FF 5A 81
					15 00 00 40 00 00 02 65 02
					39 00 00 40 00 00 05 FB D3 D3 D3 D3
					/*Active Low,ERR High*/
					39 00 00 40 00 00 03 F0 AA 10
					15 00 00 40 00 00 02 65 01
					15 00 00 00 00 00 02 CF 07
					//tp vsync
					39 00 00 40 00 00 03 F0 AA 10
					15 00 00 40 00 00 02 65 03
					15 00 00 00 00 00 02 CF 24
					/*AOD use PMIC Supply*/
					39 00 00 40 00 00 03 F0 AA 10
					15 00 00 40 00 00 02 B6 00
					//SRAM ECC by V Clear
					39 00 00 40 00 00 03 FF 5A 82
					15 00 00 40 00 00 02 65 04
					15 00 00 00 00 00 02 F8 10
					/*ACL*/
					39 00 00 40 00 00 03 F0 AA 11
					15 00 00 40 00 00 02 C0 00
					15 00 00 40 00 00 02 65 09
					39 00 00 40 00 00 04 C0 55 AA AA
					39 00 00 40 00 00 0C C1 03 34 03 99 03 34 03 FF FF A6 00
					15 00 00 40 00 00 02 55 01
					//open PMIC FD open DIC FD
					39 00 00 40 00 00 03 F0 AA 10
					15 00 00 40 00 00 02 65 07
					15 00 00 40 00 00 02 D0 00
					15 00 00 40 00 00 02 65 09
					39 00 00 40 00 00 03 D0 03 19
					15 00 00 40 00 00 02 65 0C
					15 00 00 40 00 00 02 D0 00
					15 00 00 40 00 00 02 65 0E
					39 00 00 40 00 00 03 D0 03 19
					15 00 00 40 00 00 02 65 11
					15 00 00 40 00 00 02 D0 19
					39 00 00 40 00 00 03 F0 AA 12
					15 00 00 40 00 00 02 65 0B
					15 00 00 40 00 00 02 D2 10
					39 00 00 40 00 00 03 F0 AA 10
					39 00 00 00 00 00 09 C4 34 34 34 34 34 34 34 34
					/* Display On */
					05 00 00 00 78 00 01 11
					05 00 00 00 00 00 01 29
				];
				qcom,mdss-dsi-on-command-state = "dsi_lp_mode";

				qcom,mdss-dsi-timing-switch-command = [
					/*auto 0.5HZ*/
					15 00 00 40 00 00 02 6C 00
					15 00 00 40 00 00 02 71 00
					15 00 00 40 00 00 02 75 01
					39 00 00 40 00 00 03 F0 AA 1B
					15 00 00 40 00 00 02 65 0C
					39 00 00 40 00 00 05 D5 EF EF EF EF
					39 00 00 40 00 00 0E D2 00 EF 04 03 05 07 09 0B 00 00 00 00 00
					15 00 00 40 00 00 02 D0 11
					/*FIX TE ON*/
					39 00 00 40 00 00 03 F0 AA 10
					15 00 00 00 00 00 02 CF 09
				];
				qcom,mdss-dsi-timing-switch-command-update = <0x6C 0 1>;
				qcom,mdss-dsi-timing-switch-command-state = "dsi_lp_mode";

				qcom,mdss-dsi-nolp-command = [
					05 00 00 40 00 00 01 38
					15 00 00 40 00 00 02 75 00
					39 00 00 40 00 00 03 F0 AA 1B
					15 00 00 40 00 00 02 D0 00
					39 00 00 40 00 00 03 51 00 00
					/*FIX TE OFF*/
					39 00 00 40 00 00 03 F0 AA 10
					15 00 00 00 09 00 02 CF 16
					/*auto 0.5HZ*/
					15 00 00 40 00 00 02 6C 00
					15 00 00 40 00 00 02 71 00
					15 00 00 40 00 00 02 75 01
					39 00 00 40 00 00 03 F0 AA 1B
					15 00 00 40 00 00 02 65 0C
					39 00 00 40 00 00 05 D5 EF EF EF EF
					39 00 00 40 00 00 0E D2 00 EF 04 03 05 07 09 0B 00 00 00 00 00
					15 00 00 40 00 00 02 D0 11
					/*FIX TE ON*/
					39 00 00 40 00 00 03 F0 AA 10
					15 00 00 00 00 00 02 CF 09
				];
				qcom,mdss-dsi-nolp-command-update = <0x51 4 2>, <0x6C 7 1>;
				qcom,mdss-dsi-nolp-command-state = "dsi_lp_mode";

				mi,mdss-dsi-dc-on-command = [
					15 00 00 00 00 00 02 6C 02
				];
				mi,mdss-dsi-dc-on-command-state = "dsi_lp_mode";
				mi,mdss-dsi-dc-off-command = [
					15 00 00 00 00 00 02 6C 00
				];
				mi,mdss-dsi-dc-off-command-state = "dsi_lp_mode";
			};
		};
	};
};

&dsi_o3_42_0d_0a_dsc_cmd {
	qcom,panel-supply-entries = <&dsi_panel_pwr_supply_O3>;
	qcom,panel-global-supply-entries = <&dsi_panel_pwr_supply_O3GL>;
	qcom,mdss-dsi-bl-pmic-control-type = "bl_ctrl_dcs";
	qcom,mdss-dsi-bl-min-level = <25>;
	qcom,mdss-dsi-bl-max-level = <8191>;
	qcom,bl-dsc-cmd-state = "dsi_hs_mode";
	qcom,mdss-brightness-max-level = <8191>;
	qcom,mdss-brightness-init-level = <307>;
	qcom,platform-reset-gpio = <&tlmm 98 0>;

	mi,panel-build-id-read-needed;
	mi,panel-build-id-read-length = <1>;
	mi,mdss-dsi-panel-build-id-read-command = [06 01 00 01 00 00 01 DA];
	mi,mdss-dsi-panel-build-id-read-command-state = "dsi_hs_mode";
	mi,panel-supply-different-by-country;

	//mi,disable-ic-dimming-flag;
	qcom,mdss-dsi-panel-vsync-delay;
	qcom,ulps-enabled;
	qcom,dsi-select-clocks = "pll_byte_clk0", "pll_dsi_clk0";
	qcom,mdss-dsi-clk-strength = <0xFF>;
};
